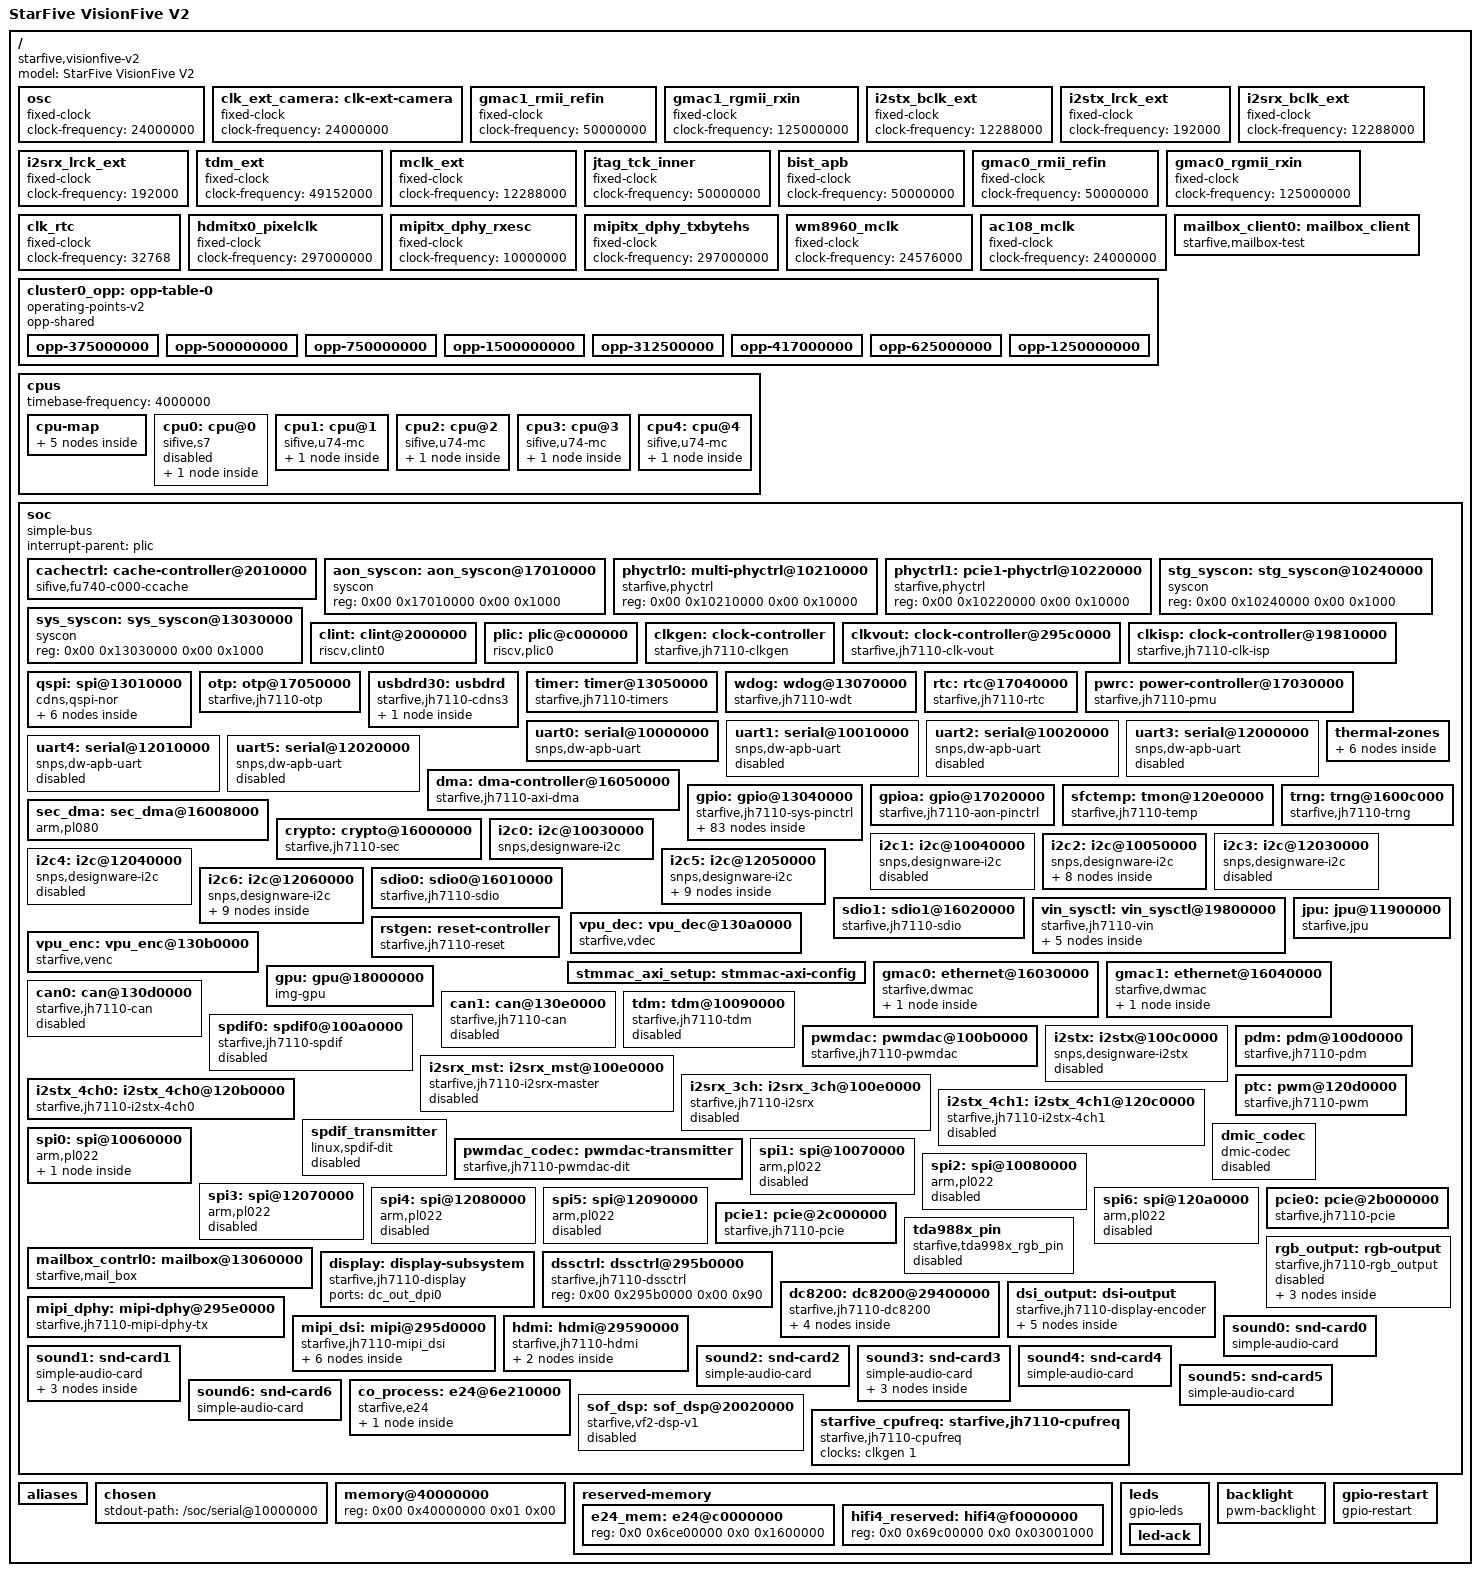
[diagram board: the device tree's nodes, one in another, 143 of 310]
/dts-v1/;

/ {
  compatible     = "starfive,visionfive-v2", "starfive,jh7110";
  #address-cells = <0x02>;
  #size-cells    = <0x02>;
  model          = "StarFive VisionFive V2";

  osc: osc {
    compatible      = "fixed-clock";
    #clock-cells    = <0x00>;
    clock-frequency = <24000000>;
  };

  clk_ext_camera: clk-ext-camera {
    compatible      = "fixed-clock";
    #clock-cells    = <0x00>;
    clock-frequency = <24000000>;
  };

  gmac1_rmii_refin: gmac1_rmii_refin {
    compatible      = "fixed-clock";
    #clock-cells    = <0x00>;
    clock-frequency = <50000000>;
  };

  gmac1_rgmii_rxin: gmac1_rgmii_rxin {
    compatible      = "fixed-clock";
    #clock-cells    = <0x00>;
    clock-frequency = <125000000>;
  };

  i2stx_bclk_ext: i2stx_bclk_ext {
    compatible      = "fixed-clock";
    #clock-cells    = <0x00>;
    clock-frequency = <12288000>;
  };

  i2stx_lrck_ext: i2stx_lrck_ext {
    compatible      = "fixed-clock";
    #clock-cells    = <0x00>;
    clock-frequency = <192000>;
  };

  i2srx_bclk_ext: i2srx_bclk_ext {
    compatible      = "fixed-clock";
    #clock-cells    = <0x00>;
    clock-frequency = <12288000>;
  };

  i2srx_lrck_ext: i2srx_lrck_ext {
    compatible      = "fixed-clock";
    #clock-cells    = <0x00>;
    clock-frequency = <192000>;
  };

  tdm_ext: tdm_ext {
    compatible      = "fixed-clock";
    #clock-cells    = <0x00>;
    clock-frequency = <49152000>;
  };

  mclk_ext: mclk_ext {
    compatible      = "fixed-clock";
    #clock-cells    = <0x00>;
    clock-frequency = <12288000>;
  };

  jtag_tck_inner: jtag_tck_inner {
    compatible      = "fixed-clock";
    #clock-cells    = <0x00>;
    clock-frequency = <50000000>;
  };

  bist_apb: bist_apb {
    compatible      = "fixed-clock";
    #clock-cells    = <0x00>;
    clock-frequency = <50000000>;
  };

  gmac0_rmii_refin: gmac0_rmii_refin {
    compatible      = "fixed-clock";
    #clock-cells    = <0x00>;
    clock-frequency = <50000000>;
  };

  gmac0_rgmii_rxin: gmac0_rgmii_rxin {
    compatible      = "fixed-clock";
    #clock-cells    = <0x00>;
    clock-frequency = <125000000>;
  };

  clk_rtc: clk_rtc {
    compatible      = "fixed-clock";
    #clock-cells    = <0x00>;
    clock-frequency = <32768>;
  };

  hdmitx0_pixelclk: hdmitx0_pixelclk {
    compatible      = "fixed-clock";
    #clock-cells    = <0x00>;
    clock-frequency = <297000000>;
  };

 mipitx_dphy_rxesc: mipitx_dphy_rxesc {
    compatible      = "fixed-clock";
    #clock-cells    = <0x00>;
    clock-frequency = <10000000>;
  };

  mipitx_dphy_txbytehs: mipitx_dphy_txbytehs {
    compatible      = "fixed-clock";
    #clock-cells    = <0x00>;
    clock-frequency = <297000000>;
  };

  wm8960_mclk: wm8960_mclk {
    compatible      = "fixed-clock";
    #clock-cells    = <0x00>;
    clock-frequency = <24576000>;
  };

  ac108_mclk: ac108_mclk {
    compatible      = "fixed-clock";
    #clock-cells    = <0x00>;
    clock-frequency = <24000000>;
  };

  cluster0_opp: opp-table-0 {
    compatible = "operating-points-v2";
    opp-shared;

    opp-375000000 {
      opp-hz        = /bits/ 64 <375000000>;
      opp-microvolt = <800000>;
    };

    opp-500000000 {
      opp-hz        = /bits/ 64 <500000000>;
      opp-microvolt = <800000>;
    };

    opp-750000000 {
      opp-hz        = /bits/ 64 <750000000>;
      opp-microvolt = <800000>;
      opp-suspend;
    };

    opp-1500000000 {
      opp-hz        = /bits/ 64 <1500000000>;
      opp-microvolt = <1040000>;
    };

    opp-312500000 {
      opp-hz        = /bits/ 64 <312500000>;
      opp-microvolt = <800000>;
    };

    opp-417000000 {
      opp-hz        = /bits/ 64 <417000000>;
      opp-microvolt = <800000>;
    };

    opp-625000000 {
      opp-hz        = /bits/ 64 <625000000>;
      opp-microvolt = <800000>;
      opp-suspend;
    };

    opp-1250000000 {
      opp-hz        = /bits/ 64 <1250000000>;
      opp-microvolt = <1000000>;
    };
  };

  cpus {
    #address-cells     = <0x01>;
    #size-cells        = <0x00>;
    timebase-frequency = <4000000>;

    cpu-map {
      cluster0 {
        core0 {
          cpu = <&cpu1>;
        };

        core1 {
          cpu = <&cpu2>;
        };

        core2 {
          cpu = <&cpu3>;
        };

        core3 {
          cpu = <&cpu4>;
        };
      };
    };

    cpu0: cpu@0 {
      compatible         = "sifive,s7", "riscv";
      reg                = <0x00>;
      d-cache-block-size = <0x40>;
      d-cache-sets       = <0x40>;
      d-cache-size       = <0x2000>;
      d-tlb-sets         = <0x01>;
      d-tlb-size         = <0x28>;
      device_type        = "cpu";
      i-cache-block-size = <0x40>;
      i-cache-sets       = <0x40>;
      i-cache-size       = <0x4000>;
      i-tlb-sets         = <0x01>;
      i-tlb-size         = <0x28>;
      mmu-type           = "riscv,sv39";
      next-level-cache   = <&cachectrl>;
      riscv,isa          = "rv64imac_zba_zbb";
      tlb-split;
      #cooling-cells     = <0x02>;
      status             = "disabled";

      cpu0intctrl: interrupt-controller {
        #interrupt-cells = <0x01>;
        compatible       = "riscv,cpu-intc";
        interrupt-controller;
      };
    };

    cpu1: cpu@1 {
      compatible          = "sifive,u74-mc", "riscv";
      reg                 = <0x01>;
      d-cache-block-size  = <0x40>;
      d-cache-sets        = <0x40>;
      d-cache-size        = <0x8000>;
      d-tlb-sets          = <0x01>;
      d-tlb-size          = <0x28>;
      device_type         = "cpu";
      i-cache-block-size  = <0x40>;
      i-cache-sets        = <0x40>;
      i-cache-size        = <0x8000>;
      i-tlb-sets          = <0x01>;
      i-tlb-size          = <0x28>;
      mmu-type            = "riscv,sv39";
      next-level-cache    = <&cachectrl>;
      riscv,isa           = "rv64imafdc_zba_zbb";
      tlb-split;
      #cooling-cells      = <0x02>;
      status              = "okay";
      operating-points-v2 = <&cluster0_opp>;
      cpu-supply          = <&cpu_vdd>;
      clocks              = <&clkgen 1>;
      clock-names         = "cpu";

      cpu1intctrl: interrupt-controller {
        #interrupt-cells = <0x01>;
        compatible       = "riscv,cpu-intc";
        interrupt-controller;
      };
    };

    cpu2: cpu@2 {
      compatible          = "sifive,u74-mc", "riscv";
      reg                 = <0x02>;
      d-cache-block-size  = <0x40>;
      d-cache-sets        = <0x40>;
      d-cache-size        = <0x8000>;
      d-tlb-sets          = <0x01>;
      d-tlb-size          = <0x28>;
      device_type         = "cpu";
      i-cache-block-size  = <0x40>;
      i-cache-sets        = <0x40>;
      i-cache-size        = <0x8000>;
      i-tlb-sets          = <0x01>;
      i-tlb-size          = <0x28>;
      mmu-type            = "riscv,sv39";
      next-level-cache    = <&cachectrl>;
      riscv,isa           = "rv64imafdc_zba_zbb";
      tlb-split;
      #cooling-cells      = <0x02>;
      status              = "okay";
      operating-points-v2 = <&cluster0_opp>;

      cpu2intctrl: interrupt-controller {
        #interrupt-cells = <0x01>;
        compatible       = "riscv,cpu-intc";
        interrupt-controller;
      };
    };

    cpu3: cpu@3 {
      compatible          = "sifive,u74-mc", "riscv";
      reg                 = <0x03>;
      d-cache-block-size  = <0x40>;
      d-cache-sets        = <0x40>;
      d-cache-size        = <0x8000>;
      d-tlb-sets          = <0x01>;
      d-tlb-size          = <0x28>;
      device_type         = "cpu";
      i-cache-block-size  = <0x40>;
      i-cache-sets        = <0x40>;
      i-cache-size        = <0x8000>;
      i-tlb-sets          = <0x01>;
      i-tlb-size          = <0x28>;
      mmu-type            = "riscv,sv39";
      next-level-cache    = <&cachectrl>;
      riscv,isa           = "rv64imafdc_zba_zbb";
      tlb-split;
      #cooling-cells      = <0x02>;
      status              = "okay";
      operating-points-v2 = <&cluster0_opp>;

      cpu3intctrl: interrupt-controller {
        #interrupt-cells = <0x01>;
        compatible       = "riscv,cpu-intc";
        interrupt-controller;
      };
    };

    cpu4: cpu@4 {
      compatible          = "sifive,u74-mc", "riscv";
      reg                 = <0x04>;
      d-cache-block-size  = <0x40>;
      d-cache-sets        = <0x40>;
      d-cache-size        = <0x8000>;
      d-tlb-sets          = <0x01>;
      d-tlb-size          = <0x28>;
      device_type         = "cpu";
      i-cache-block-size  = <0x40>;
      i-cache-sets        = <0x40>;
      i-cache-size        = <0x8000>;
      i-tlb-sets          = <0x01>;
      i-tlb-size          = <0x28>;
      mmu-type            = "riscv,sv39";
      next-level-cache    = <&cachectrl>;
      riscv,isa           = "rv64imafdc_zba_zbb";
      tlb-split;
      #cooling-cells      = <0x02>;
      status              = "okay";
      operating-points-v2 = <&cluster0_opp>;

      cpu4intctrl: interrupt-controller {
        #interrupt-cells = <0x01>;
        compatible       = "riscv,cpu-intc";
        interrupt-controller;
      };
    };
  };

  mailbox_client0: mailbox_client {
    compatible = "starfive,mailbox-test";
    mbox-names = "rx", "tx";
    mboxes     = <&mailbox_contrl0 0 1>, <&mailbox_contrl0 1 0>;
    status     = "okay";
  };

  soc: soc {
    compatible       = "simple-bus";
    interrupt-parent = <&plic>;
    #address-cells   = <0x02>;
    #size-cells      = <0x02>;
    #clock-cells     = <0x01>;
    ranges;

    cachectrl: cache-controller@2010000 {
      compatible       = "sifive,fu740-c000-ccache", "cache";
      reg              = <0x00 0x2010000 0x00 0x4000 0x00 0x8000000 0x00 0x2000000>;
      reg-names        = "control", "sideband";
      interrupts       = <0x01 0x03 0x04 0x02>;
      cache-block-size = <0x40>;
      cache-level      = <0x02>;
      cache-sets       = <0x800>;
      cache-size       = <0x200000>;
      cache-unified;
      uncached-offset  = <0x04 0x00>;
    };

    aon_syscon: aon_syscon@17010000 {
      compatible = "syscon";
      reg        = <0x00 0x17010000 0x00 0x1000>;
    };

    phyctrl0: multi-phyctrl@10210000 {
      compatible = "starfive,phyctrl";
      reg        = <0x00 0x10210000 0x00 0x10000>;
    };

    phyctrl1: pcie1-phyctrl@10220000 {
      compatible = "starfive,phyctrl";
      reg        = <0x00 0x10220000 0x00 0x10000>;
    };

    stg_syscon: stg_syscon@10240000 {
      compatible = "syscon";
      reg        = <0x00 0x10240000 0x00 0x1000>;
    };

    sys_syscon: sys_syscon@13030000 {
      compatible = "syscon";
      reg        = <0x00 0x13030000 0x00 0x1000>;
    };

    clint: clint@2000000 {
      compatible          = "riscv,clint0";
      reg                 = <0x00 0x2000000 0x00 0x10000>;
      reg-names           = "control";
      interrupts-extended = <
        &cpu0intctrl 3 &cpu0intctrl 7
        &cpu1intctrl 3 &cpu1intctrl 7
        &cpu2intctrl 3 &cpu2intctrl 7
        &cpu3intctrl 3 &cpu3intctrl 7
        &cpu4intctrl 3 &cpu4intctrl 7
      >;
      #interrupt-cells    = <0x01>;
    };

    plic: plic@c000000 {
      compatible          = "riscv,plic0";
      reg                 = <0x00 0xc000000 0x00 0x4000000>;
      reg-names           = "control";
      interrupts-extended = <
        &cpu0intctrl 11
        &cpu1intctrl 11 &cpu1intctrl 9
        &cpu2intctrl 11 &cpu2intctrl 9
        &cpu3intctrl 11 &cpu3intctrl 9
        &cpu4intctrl 11 &cpu4intctrl 9
      >;
      interrupt-controller;
      #interrupt-cells    = <0x01>;
      riscv,max-priority  = <0x07>;
      riscv,ndev          = <0x88>;
    };

    clkgen: clock-controller {
      compatible          = "starfive,jh7110-clkgen";
      reg                 = <0x00 0x13020000 0x00 0x10000>, <0x00 0x10230000 0x00 0x10000>, <0x00 0x17000000 0x00 0x10000>;
      reg-names           = "sys", "stg", "aon";
      clocks              = <&osc>, <&gmac1_rmii_refin>, <&gmac1_rgmii_rxin>, <&i2stx_bclk_ext>, <&i2stx_lrck_ext>, <&i2srx_bclk_ext>, <&i2srx_lrck_ext>, <&tdm_ext>, <&mclk_ext>, <&jtag_tck_inner>, <&bist_apb>, <&clk_rtc>, <&gmac0_rmii_refin>, <&gmac0_rgmii_rxin>;
      clock-names         = "osc", "gmac1_rmii_refin", "gmac1_rgmii_rxin", "i2stx_bclk_ext", "i2stx_lrck_ext", "i2srx_bclk_ext", "i2srx_lrck_ext", "tdm_ext", "mclk_ext", "jtag_tck_inner", "bist_apb", "clk_rtc", "gmac0_rmii_refin", "gmac0_rgmii_rxin";
      #clock-cells        = <0x01>;
      starfive,sys-syscon = <&sys_syscon 0x18 0x1c 0x20 0x24 0x28 0x2c 0x30 0x34>;
      status              = "okay";
    };

    clkvout: clock-controller@295c0000 {
      compatible    = "starfive,jh7110-clk-vout";
      reg           = <0x00 0x295c0000 0x00 0x10000>;
      reg-names     = "vout";
      clocks        = <&hdmitx0_pixelclk>, <&mipitx_dphy_rxesc>, <&mipitx_dphy_txbytehs>, <&clkgen 58>, <&clkgen 61>;
      clock-names   = "hdmitx0_pixelclk", "mipitx_dphy_rxesc", "mipitx_dphy_txbytehs", "vout_src", "vout_top_ahb";
      resets        = <&rstgen 43>;
      reset-names   = "vout_src";
      #clock-cells  = <0x01>;
      power-domains = <&pwrc 4>;
      status        = "okay";
    };

    clkisp: clock-controller@19810000 {
      compatible    = "starfive,jh7110-clk-isp";
      reg           = <0x00 0x19810000 0x00 0x10000>;
      reg-names     = "isp";
      #clock-cells  = <0x01>;
      clocks        = <&clkgen 266>, <&clkgen 51>, <&clkgen 52>, <&clkgen 53>;
      clock-names   = "u0_dom_isp_top_clk_dom_isp_top_clk_dvp", "u0_dom_isp_top_clk_dom_isp_top_clk_ispcore_2x", "u0_dom_isp_top_clk_dom_isp_top_clk_isp_axi", "u0_sft7110_noc_bus_clk_isp_axi";
      resets        = <&rstgen 41>, <&rstgen 42>, <&rstgen 28>;
      reset-names   = "rst_isp_top_n", "rst_isp_top_axi", "rst_isp_noc_bus_n";
      power-domains = <&pwrc 5>;
      status        = "okay";
    };

    qspi: spi@13010000 {
      compatible           = "cdns,qspi-nor";
      #address-cells       = <0x01>;
      #size-cells          = <0x00>;
      reg                  = <0x00 0x13010000 0x00 0x10000>, <0x00 0x21000000 0x00 0x400000>;
      interrupts           = <0x19>;
      clocks               = <&clkgen 90>, <&clkgen 88>, <&clkgen 10>, <&clkgen 87>, <&clkgen 89>;
      clock-names          = "clk_ref", "clk_apb", "ahb1", "clk_ahb", "clk_src";
      resets               = <&rstgen 62>, <&rstgen 61>, <&rstgen 63>;
      cdns,fifo-depth      = <0x100>;
      cdns,fifo-width      = <0x04>;
      cdns,trigger-address = <0x00>;
      spi-max-frequency    = <0xee6b280>;

      nor_flash: nor-flash@0 {
        compatible        = "jedec,spi-nor";
        reg               = <0x00>;
        cdns,read-delay   = <0x05>;
        spi-max-frequency = <100000000>;
        cdns,tshsl-ns     = <0x01>;
        cdns,tsd2d-ns     = <0x01>;
        cdns,tchsh-ns     = <0x01>;
        cdns,tslch-ns     = <0x01>;
        status            = "okay";

        partitions {
          compatible     = "fixed-partitions";
          #address-cells = <0x01>;
          #size-cells    = <0x01>;

          spl@0 {
            reg = <0x00 0x40000>;
          };

          uboot-env@100000 {
            reg = <0xf0000 0x10000>;
          };

          uboot@100000 {
            reg = <0x100000 0x300000>;
          };

          data@f00000 {
            reg = <0xf00000 0x100000>;
          };
        };
      };
    };

    otp: otp@17050000 {
      compatible      = "starfive,jh7110-otp";
      reg             = <0x00 0x17050000 0x00 0x10000>;
      clock-frequency = <4000000>;
      clocks          = <&clkgen 228>;
      clock-names     = "apb";
    };

    usbdrd30: usbdrd {
      compatible          = "starfive,jh7110-cdns3";
      reg                 = <0x00 0x10210000 0x00 0x1000>, <0x00 0x10200000 0x00 0x1000>;
      clocks              = <&clkgen 95>, <&clkgen 196>, <&clkgen 194>, <&clkgen 195>, <&clkgen 191>, <&clkgen 193>, <&clkgen 192>;
      clock-names         = "125m", "app", "lpm", "stb", "apb", "axi", "utmi";
      resets              = <&rstgen 138>, <&rstgen 136>, <&rstgen 135>, <&rstgen 137>;
      reset-names         = "pwrup", "apb", "axi", "utmi";
      starfive,stg-syscon = <&stg_syscon 0x04 0xc4 0x148 0x1f4>;
      starfive,sys-syscon = <&sys_syscon 0x18>;
      status              = "okay";
      #address-cells      = <0x02>;
      #size-cells         = <0x02>;
      #interrupt-cells    = <0x01>;
      ranges;
      starfive,usb2-only;
      dr_mode             = "peripheral";

      usbdrd_cdns3: usb@10100000 {
        compatible      = "cdns,usb3";
        dma-coherent;
        reg             = <0x00 0x10100000 0x00 0x10000>, <0x00 0x10110000 0x00 0x10000>, <0x00 0x10120000 0x00 0x10000>;
        reg-names       = "otg", "xhci", "dev";
        interrupts      = <0x64 0x6c 0x6e>;
        interrupt-names = "host", "peripheral", "otg";
        phy-names       = "cdns3,usb3-phy", "cnds3,usb2-phy";
        maximum-speed   = "super-speed";
      };
    };

    timer: timer@13050000 {
      compatible      = "starfive,jh7110-timers";
      reg             = <0x00 0x13050000 0x00 0x10000>;
      interrupts      = <0x45 0x46 0x47 0x48>;
      interrupt-names = "timer0", "timer1", "timer2", "timer3";
      clocks          = <&clkgen 125>, <&clkgen 126>, <&clkgen 127>, <&clkgen 128>, <&clkgen 124>;
      clock-names     = "timer0", "timer1", "timer2", "timer3", "apb_clk";
      resets          = <&rstgen 118>, <&rstgen 119>, <&rstgen 120>, <&rstgen 121>, <&rstgen 117>;
      reset-names     = "timer0", "timer1", "timer2", "timer3", "apb_rst";
      clock-frequency = <0x16e3600>;
      status          = "okay";
    };

    wdog: wdog@13070000 {
      compatible      = "starfive,jh7110-wdt";
      reg             = <0x00 0x13070000 0x00 0x10000>;
      interrupts      = <0x44>;
      interrupt-names = "wdog";
      clocks          = <&clkgen 123>, <&clkgen 122>;
      clock-names     = "core_clk", "apb_clk";
      resets          = <&rstgen 109>, <&rstgen 110>;
      reset-names     = "rst_apb", "rst_core";
      timeout-sec     = <0x0f>;
      status          = "okay";
    };

    rtc: rtc@17040000 {
      compatible         = "starfive,jh7110-rtc";
      reg                = <0x00 0x17040000 0x00 0x10000>;
      interrupts         = <0x0a 0x0b 0x0c>;
      interrupt-names    = "rtc_ms_pulse", "rtc_sec_pulse", "rtc";
      clocks             = <&clkgen 229>, <&clkgen 232>;
      clock-names        = "pclk", "cal_clk";
      resets             = <&rstgen 167>, <&rstgen 165>, <&rstgen 166>;
      reset-names        = "rst_osc", "rst_apb", "rst_cal";
      rtc,cal-clock-freq = <1000000>;
      status             = "okay";
    };

    pwrc: power-controller@17030000 {
      compatible          = "starfive,jh7110-pmu";
      reg                 = <0x00 0x17030000 0x00 0x10000>;
      interrupts          = <0x6f>;
      #power-domain-cells = <0x01>;
      status              = "okay";
    };

    uart0: serial@10000000 {
      compatible    = "snps,dw-apb-uart";
      reg           = <0x00 0x10000000 0x00 0x10000>;
      reg-io-width  = <0x04>;
      reg-shift     = <0x02>;
      clocks        = <&clkgen 146>, <&clkgen 145>;
      clock-names   = "baudclk", "apb_pclk";
      resets        = <&rstgen 83>, <&rstgen 84>;
      interrupts    = <0x20>;
      status        = "okay";
      pinctrl-names = "default";
      pinctrl-0     = <&uart0_pins>;
    };

    uart1: serial@10010000 {
      compatible   = "snps,dw-apb-uart";
      reg          = <0x00 0x10010000 0x00 0x10000>;
      reg-io-width = <0x04>;
      reg-shift    = <0x02>;
      clocks       = <&clkgen 148>, <&clkgen 147>;
      clock-names  = "baudclk", "apb_pclk";
      resets       = <&rstgen 85>, <&rstgen 86>;
      interrupts   = <0x21>;
      status       = "disabled";
    };

    uart2: serial@10020000 {
      compatible   = "snps,dw-apb-uart";
      reg          = <0x00 0x10020000 0x00 0x10000>;
      reg-io-width = <0x04>;
      reg-shift    = <0x02>;
      clocks       = <&clkgen 150>, <&clkgen 149>;
      clock-names  = "baudclk", "apb_pclk";
      resets       = <&rstgen 87>, <&rstgen 88>;
      interrupts   = <0x22>;
      status       = "disabled";
    };

    uart3: serial@12000000 {
      compatible   = "snps,dw-apb-uart";
      reg          = <0x00 0x12000000 0x00 0x10000>;
      reg-io-width = <0x04>;
      reg-shift    = <0x02>;
      clocks       = <&clkgen 152>, <&clkgen 151>;
      clock-names  = "baudclk", "apb_pclk";
      resets       = <&rstgen 89>, <&rstgen 90>;
      interrupts   = <0x2d>;
      status       = "disabled";
    };

    uart4: serial@12010000 {
      compatible   = "snps,dw-apb-uart";
      reg          = <0x00 0x12010000 0x00 0x10000>;
      reg-io-width = <0x04>;
      reg-shift    = <0x02>;
      clocks       = <&clkgen 154>, <&clkgen 153>;
      clock-names  = "baudclk", "apb_pclk";
      resets       = <&rstgen 91>, <&rstgen 92>;
      interrupts   = <0x2e>;
      status       = "disabled";
    };

    uart5: serial@12020000 {
      compatible   = "snps,dw-apb-uart";
      reg          = <0x00 0x12020000 0x00 0x10000>;
      reg-io-width = <0x04>;
      reg-shift    = <0x02>;
      clocks       = <&clkgen 156>, <&clkgen 155>;
      clock-names  = "baudclk", "apb_pclk";
      resets       = <&rstgen 93>, <&rstgen 94>;
      interrupts   = <0x2f>;
      status       = "disabled";
    };

    dma: dma-controller@16050000 {
      compatible             = "starfive,jh7110-axi-dma";
      dma-coherent;
      reg                    = <0x00 0x16050000 0x00 0x10000>;
      clocks                 = <&clkgen 217>, <&clkgen 218>, <&clkgen 96>;
      clock-names            = "core-clk", "cfgr-clk", "noc-clk";
      resets                 = <&rstgen 133>, <&rstgen 134>, <&rstgen 30>;
      interrupts             = <0x49>;
      #dma-cells             = <0x01>;
      dma-channels           = <0x04>;
      snps,dma-masters       = <0x01>;
      snps,data-width        = <0x03>;
      snps,block-size        = <0x10000 0x10000 0x10000 0x10000>;
      snps,priority          = <0x00 0x01 0x02 0x03>;
      snps,axi-max-burst-len = <0x0f>;
      status                 = "okay";
    };

    gpio: gpio@13040000 {
      compatible  = "starfive,jh7110-sys-pinctrl";
      reg         = <0x00 0x13040000 0x00 0x10000>;
      reg-names   = "control";
      clocks      = <&clkgen 112>;
      resets      = <&rstgen 2>;
      interrupts  = <0x56>;
      interrupt-controller;
      #gpio-cells = <0x02>;
      ngpios      = <0x40>;
      status      = "okay";

      i2c0_pins: i2c0-pins {
        i2c0-pins-scl {
          starfive,pins          = <0x39>;
          starfive,pinmux        = <0x2ac 0x0c 0x7000 0x00>;
          starfive,pin-ioconfig  = <0x09>;
          starfive,pin-gpio-dout = <0x00>;
          starfive,pin-gpio-doen = <0x05>;
          starfive,pin-gpio-din  = <0x09>;
        };

        i2c0-pins-sda {
          starfive,pins          = <0x3a>;
          starfive,pinmux        = <0x2ac 0x0f 0x38000 0x00>;
          starfive,pin-ioconfig  = <0x09>;
          starfive,pin-gpio-dout = <0x00>;
          starfive,pin-gpio-doen = <0x06>;
          starfive,pin-gpio-din  = <0x0a>;
        };
      };

      i2c5_pins: i2c5-pins {
        i2c5-pins-scl {
          starfive,pins          = <0x13>;
          starfive,pinmux        = <0x29c 0x1d 0xe0000000 0x00>;
          starfive,pin-ioconfig  = <0x09>;
          starfive,pin-gpio-dout = <0x00>;
          starfive,pin-gpio-doen = <0x2a>;
          starfive,pin-gpio-din  = <0x4f>;
        };

        i2c5-pins-sda {
          starfive,pins          = <0x14>;
          starfive,pinmux        = <0x2a0 0x00 0x07 0x00>;
          starfive,pin-ioconfig  = <0x09>;
          starfive,pin-gpio-dout = <0x00>;
          starfive,pin-gpio-doen = <0x2b>;
          starfive,pin-gpio-din  = <0x50>;
        };
      };

      i2c6_pins: i2c6-pins {
        i2c6-pins-scl {
          starfive,pins          = <0x10>;
          starfive,pinmux        = <0x29c 0x14 0x700000 0x00>;
          starfive,pin-ioconfig  = <0x09>;
          starfive,pin-gpio-dout = <0x00>;
          starfive,pin-gpio-doen = <0x2e>;
          starfive,pin-gpio-din  = <0x56>;
        };

        i2c6-pins-sda {
          starfive,pins          = <0x11>;
          starfive,pinmux        = <0x29c 0x17 0x3800000 0x00>;
          starfive,pin-ioconfig  = <0x09>;
          starfive,pin-gpio-dout = <0x00>;
          starfive,pin-gpio-doen = <0x2f>;
          starfive,pin-gpio-din  = <0x57>;
        };
      };

      pwmdac0_pins: pwmdac0-pins {
        pwmdac0-pins-left {
          starfive,pins          = <0x21>;
          starfive,pinmux        = <0x2a4 0x09 0xe00 0x00>;
          starfive,pin-ioconfig  = <0x09>;
          starfive,pin-gpio-dout = <0x1c>;
          starfive,pin-gpio-doen = <0x00>;
        };

        pwmdac0-pins-right {
          starfive,pins          = <0x22>;
          starfive,pinmux        = <0x2a4 0x0c 0x7000 0x00>;
          starfive,pin-ioconfig  = <0x09>;
          starfive,pin-gpio-dout = <0x1d>;
          starfive,pin-gpio-doen = <0x00>;
        };
      };

      pwm_pins: pwm-pins {
        pwm_ch0-pins {
          starfive,pins          = <0x2e>;
          starfive,pinmux        = <0x2a8 0x0f 0x38000 0x00>;
          starfive,pin-ioconfig  = <0x01>;
          starfive,pin-gpio-dout = <0x18>;
          starfive,pin-gpio-doen = <0x09>;
        };

        pwm_ch1-pins {
          starfive,pins          = <0x3b>;
          starfive,pinmux        = <0x2ac 0x12 0x1c0000 0x00>;
          starfive,pin-ioconfig  = <0x01>;
          starfive,pin-gpio-dout = <0x19>;
          starfive,pin-gpio-doen = <0x0a>;
        };

        pwm_ch2-pins {
          starfive,pins          = <0x18>;
          starfive,pinmux        = <0x2a0 0x0c 0x7000 0x00>;
          starfive,pin-ioconfig  = <0x01>;
          starfive,pin-gpio-dout = <0x1a>;
          starfive,pin-gpio-doen = <0x0b>;
        };
      };

      ssp0_pins: ssp0-pins {
        ssp0-pins_tx {
          starfive,pins          = <0x34>;
          starfive,pinmux        = <0x2ac 0x00 0x03 0x00>;
          starfive,pin-ioconfig  = <0x01>;
          starfive,pin-gpio-dout = <0x20>;
          starfive,pin-gpio-doen = <0x00>;
        };

        ssp0-pins_rx {
          starfive,pins          = <0x35>;
          starfive,pinmux        = <0x2ac 0x02 0x0c 0x00>;
          starfive,pin-ioconfig  = <0x01>;
          starfive,pin-gpio-doen = <0x01>;
          starfive,pin-gpio-din  = <0x1c>;
        };

        ssp0-pins_clk {
          starfive,pins          = <0x30>;
          starfive,pinmux        = <0x2a8 0x15 0xe00000 0x00>;
          starfive,pin-ioconfig  = <0x01>;
          starfive,pin-gpio-dout = <0x1e>;
          starfive,pin-gpio-doen = <0x00>;
        };

        ssp0-pins_cs {
          starfive,pins          = <0x31>;
          starfive,pinmux        = <0x2a8 0x18 0x7000000 0x00>;
          starfive,pin-ioconfig  = <0x01>;
          starfive,pin-gpio-dout = <0x1f>;
          starfive,pin-gpio-doen = <0x00>;
        };
      };

      pcie0_perst_default: pcie0_perst_default {
        perst-pins {
          starfive,pins          = <0x1a>;
          starfive,pinmux        = <0x2a0 0x12 0x1c0000 0x00>;
          starfive,pin-ioconfig  = <0x01>;
          starfive,pin-gpio-dout = <0x01>;
          starfive,pin-gpio-doen = <0x00>;
        };
      };

      pcie0_perst_active: pcie0_perst_active {
        perst-pins {
          starfive,pins          = <0x1a>;
          starfive,pinmux        = <0x2a0 0x12 0x1c0000 0x00>;
          starfive,pin-ioconfig  = <0x01>;
          starfive,pin-gpio-dout = <0x00>;
          starfive,pin-gpio-doen = <0x00>;
        };
      };

      pcie0_wake_default: pcie0_wake_default {
        wake-pins {
          starfive,pins          = <0x20>;
          starfive,pinmux        = <0x2a4 0x06 0x1c0 0x00>;
          starfive,pin-ioconfig  = <0x01>;
          starfive,pin-gpio-doen = <0x01>;
        };
      };

      pcie0_clkreq_default: pcie0_clkreq_default {
        clkreq-pins {
          starfive,pins          = <0x1b>;
          starfive,pinmux        = <0x2a0 0x15 0xe00000 0x00>;
          starfive,pin-ioconfig  = <0x01>;
          starfive,pin-gpio-doen = <0x01>;
        };
      };

      pcie1_perst_default: pcie1_perst_default {
        perst-pins {
          starfive,pins          = <0x1c>;
          starfive,pinmux        = <0x2a0 0x18 0x7000000 0x00>;
          starfive,pin-ioconfig  = <0x01>;
          starfive,pin-gpio-dout = <0x01>;
          starfive,pin-gpio-doen = <0x00>;
        };
      };

      pcie1_perst_active: pcie1_perst_active {
        perst-pins {
          starfive,pins          = <0x1c>;
          starfive,pinmux        = <0x2a0 0x18 0x7000000 0x00>;
          starfive,pin-ioconfig  = <0x01>;
          starfive,pin-gpio-dout = <0x00>;
          starfive,pin-gpio-doen = <0x00>;
        };
      };

      pcie1_wake_default: pcie1_wake_default {
        wake-pins {
          starfive,pins          = <0x15>;
          starfive,pinmux        = <0x2a0 0x03 0x38 0x00>;
          starfive,pin-ioconfig  = <0x01>;
          starfive,pin-gpio-doen = <0x01>;
        };
      };

      pcie1_clkreq_default: pcie1_clkreq_default {
        clkreq-pins {
          starfive,pins          = <0x1d>;
          starfive,pinmux        = <0x2a0 0x1b 0x38000000 0x00>;
          starfive,pin-ioconfig  = <0x01>;
          starfive,pin-gpio-doen = <0x01>;
        };
      };

      usb_pins: usb-pins {
        drive-vbus-pin {
          starfive,pins          = <0x19>;
          starfive,pinmux        = <0x2a0 0x0f 0x38000 0x00>;
          starfive,pin-ioconfig  = <0x01>;
          starfive,pin-gpio-dout = <0x07>;
          starfive,pin-gpio-doen = <0x00>;
        };
      };

      i2srx_pins: i2srx-pins {
        i2srx-pins0 {
          starfive,pins          = <0x3d>;
          starfive,pinmux        = <0x2ac 0x18 0x7000000 0x00>;
          starfive,pin-ioconfig  = <0x01>;
          starfive,pin-gpio-doen = <0x01>;
          starfive,pin-gpio-din  = <0x17>;
        };
      };

      i2s_clk_pins: i2s-clk0 {
        i2s-clk0_bclk {
          starfive,pins          = <0x26>;
          starfive,pinmux        = <0x2a4 0x17 0x3800000 0x00>;
          starfive,pin-ioconfig  = <0x01>;
          starfive,pin-gpio-din  = <0x21 0x1f>;
          starfive,pin-gpio-doen = <0x01>;
        };

        i2s-clk0_lrclk {
          starfive,pins          = <0x3f>;
          starfive,pinmux        = <0x2ac 0x1e 0xc0000000 0x00>;
          starfive,pin-ioconfig  = <0x01>;
          starfive,pin-gpio-din  = <0x22 0x20>;
          starfive,pin-gpio-doen = <0x01>;
        };
      };

      i2stx_pins: i2stx-pins {
        i2stx-pins0 {
          starfive,pins          = <0x2c>;
          starfive,pinmux        = <0x2a8 0x09 0xe00 0x00>;
          starfive,pin-ioconfig  = <0x01>;
          starfive,pin-gpio-dout = <0x45>;
          starfive,pin-gpio-doen = <0x00>;
        };
      };

      uart0_pins: uart0-pins {
        uart0-pins-tx {
          starfive,pins          = <0x05>;
          starfive,pin-ioconfig  = <0x07>;
          starfive,pin-gpio-dout = <0x14>;
          starfive,pin-gpio-doen = <0x00>;
        };

        uart0-pins-rx {
          starfive,pins          = <0x06>;
          starfive,pinmux        = <0x2b0 0x00 0x03 0x00>;
          starfive,pin-ioconfig  = <0x09>;
          starfive,pin-gpio-doen = <0x01>;
          starfive,pin-gpio-din  = <0x0e>;
        };
      };

      i2c2_pins: i2c2-pins {
        i2c2-pins-scl {
          starfive,pins          = <0x03>;
          starfive,pin-ioconfig  = <0x09>;
          starfive,pin-gpio-dout = <0x00>;
          starfive,pin-gpio-doen = <0x1e>;
          starfive,pin-gpio-din  = <0x3b>;
        };

        i2c2-pins-sda {
          starfive,pins          = <0x02>;
          starfive,pin-ioconfig  = <0x09>;
          starfive,pin-gpio-dout = <0x00>;
          starfive,pin-gpio-doen = <0x1f>;
          starfive,pin-gpio-din  = <0x3c>;
        };
      };

      mmc0_pins: mmc0-pins {
        mmc0-pins-rest {
          starfive,pins          = <0x3e>;
          starfive,pinmux        = <0x2ac 0x1b 0x38000000 0x00>;
          starfive,pin-ioconfig  = <0x09>;
          starfive,pin-gpio-dout = <0x13>;
          starfive,pin-gpio-doen = <0x00>;
        };

        mmc0-pins-cLK {
          starfive,pins         = <0x40>;
          starfive,pin-ioconfig = <0x2d>;
        };

        mmc0-pins-cmd {
          starfive,pins         = <0x41>;
          starfive,pin-ioconfig = <0x0b>;
        };

        mmc0-pins-data0 {
          starfive,pins         = <0x42>;
          starfive,pin-ioconfig = <0x0b>;
        };

        mmc0-pins-data1 {
          starfive,pins         = <0x43>;
          starfive,pin-ioconfig = <0x0b>;
        };

        mmc0-pins-data2 {
          starfive,pins         = <0x44>;
          starfive,pin-ioconfig = <0x0b>;
        };

        mmc0-pins-data3 {
          starfive,pins         = <0x45>;
          starfive,pin-ioconfig = <0x0b>;
        };

        mmc0-pins-data4 {
          starfive,pins         = <0x46>;
          starfive,pin-ioconfig = <0x0b>;
        };

        mmc0-pins-data5 {
          starfive,pins         = <0x47>;
          starfive,pin-ioconfig = <0x0b>;
        };

        mmc0-pins-data6 {
          starfive,pins         = <0x48>;
          starfive,pin-ioconfig = <0x0b>;
        };

        mmc0-pins-data7 {
          starfive,pins         = <0x49>;
          starfive,pin-ioconfig = <0x0b>;
        };
      };

      sdcard1_pins: sdcard1-pins {
        sdcard1-pins0 {
          starfive,pins          = <0x0a>;
          starfive,pinmux        = <0x29c 0x02 0x1c 0x00>;
          starfive,pin-ioconfig  = <0x2d>;
          starfive,pin-gpio-dout = <0x37>;
          starfive,pin-gpio-doen = <0x00>;
        };

        sdcard1-pins1 {
          starfive,pins          = <0x09>;
          starfive,pinmux        = <0x2b0 0x08 0x700 0x00>;
          starfive,pin-ioconfig  = <0x0b>;
          starfive,pin-gpio-dout = <0x39>;
          starfive,pin-gpio-doen = <0x13>;
          starfive,pin-gpio-din  = <0x2c>;
        };

        sdcard1-pins2 {
          starfive,pins          = <0x0b>;
          starfive,pinmux        = <0x29c 0x05 0xe0 0x00>;
          starfive,pin-ioconfig  = <0x0b>;
          starfive,pin-gpio-dout = <0x3a>;
          starfive,pin-gpio-doen = <0x14>;
          starfive,pin-gpio-din  = <0x2d>;
        };

        sdcard1-pins3 {
          starfive,pins          = <0x0c>;
          starfive,pinmux        = <0x29c 0x08 0x700 0x00>;
          starfive,pin-ioconfig  = <0x0b>;
          starfive,pin-gpio-dout = <0x3b>;
          starfive,pin-gpio-doen = <0x15>;
          starfive,pin-gpio-din  = <0x2e>;
        };

        sdcard1-pins4 {
          starfive,pins          = <0x07>;
          starfive,pinmux        = <0x2b0 0x02 0x1c 0x00>;
          starfive,pin-ioconfig  = <0x0b>;
          starfive,pin-gpio-dout = <0x3c>;
          starfive,pin-gpio-doen = <0x16>;
          starfive,pin-gpio-din  = <0x2f>;
        };

        sdcard1-pins5 {
          starfive,pins          = <0x08>;
          starfive,pinmux        = <0x2b0 0x05 0xe0 0x00>;
          starfive,pin-ioconfig  = <0x0b>;
          starfive,pin-gpio-dout = <0x3d>;
          starfive,pin-gpio-doen = <0x17>;
          starfive,pin-gpio-din  = <0x30>;
        };
      };

      inno_hdmi_pins: inno_hdmi-pins {
        inno_hdmi-scl {
          starfive,pins          = <0x00>;
          starfive,pin-ioconfig  = <0x09>;
          starfive,pin-gpio-dout = <0x0b>;
          starfive,pin-gpio-doen = <0x03>;
          starfive,pin-gpio-din  = <0x06>;
        };

        inno_hdmi-sda {
          starfive,pins          = <0x01>;
          starfive,pin-ioconfig  = <0x09>;
          starfive,pin-gpio-dout = <0x0c>;
          starfive,pin-gpio-doen = <0x04>;
          starfive,pin-gpio-din  = <0x07>;
        };

        inno_hdmi-cec-pins {
          starfive,pins          = <0x0e>;
          starfive,pin-ioconfig  = <0x09>;
          starfive,pin-gpio-doen = <0x02>;
          starfive,pin-gpio-dout = <0x0a>;
          starfive,pin-gpio-din  = <0x05>;
        };

        inno_hdmi-hpd-pins {
          starfive,pins          = <0x0f>;
          starfive,pin-ioconfig  = <0x01>;
          starfive,pin-gpio-doen = <0x01>;
          starfive,pin-gpio-din  = <0x08>;
        };
      };

      mclk_ext_pins: mclk_ext_pins {
        mclk_ext_pins {
          starfive,pins          = <0x04>;
          starfive,pin-ioconfig  = <0x01>;
          starfive,pin-gpio-din  = <0x1e>;
          starfive,pin-gpio-doen = <0x01>;
        };
      };

     tdm0_pins: tdm0-pins {
        tdm0-pins-tx {
          starfive,pins          = <0x2c>;
          starfive,pinmux        = <0x2a8 0x09 0xe00 0x00>;
          starfive,pin-ioconfig  = <0x01>;
          starfive,pin-gpio-dout = <0x29>;
          starfive,pin-gpio-doen = <0x00>;
        };

        tdm0-pins-rx {
          starfive,pins          = <0x3d>;
          starfive,pinmux        = <0x2ac 0x18 0x7000000 0x00>;
          starfive,pin-ioconfig  = <0x01>;
          starfive,pin-gpio-doen = <0x01>;
          starfive,pin-gpio-din  = <0x24>;
        };

        tdm0-pins-sync {
          starfive,pins          = <0x3f>;
          starfive,pinmux        = <0x2ac 0x1e 0xc0000000 0x00>;
          starfive,pin-ioconfig  = <0x01>;
          starfive,pin-gpio-doen = <0x01>;
          starfive,pin-gpio-din  = <0x25>;
        };

        tdm0-pins-pcmclk {
          starfive,pins          = <0x26>;
          starfive,pinmux        = <0x2a4 0x17 0x3800000 0x00>;
          starfive,pin-ioconfig  = <0x01>;
          starfive,pin-gpio-doen = <0x01>;
          starfive,pin-gpio-din  = <0x23>;
        };
      };
    };

    gpioa: gpio@17020000 {
      compatible  = "starfive,jh7110-aon-pinctrl";
      reg         = <0x00 0x17020000 0x00 0x10000>;
      reg-names   = "control";
      resets      = <&rstgen 162>;
      interrupts  = <0x55>;
      interrupt-controller;
      #gpio-cells = <0x02>;
      ngpios      = <0x04>;
      status      = "okay";
    };

    sfctemp: tmon@120e0000 {
      compatible            = "starfive,jh7110-temp";
      reg                   = <0x00 0x120e0000 0x00 0x10000>;
      interrupts            = <0x51>;
      clocks                = <&clkgen 130>, <&clkgen 129>;
      clock-names           = "sense", "bus";
      resets                = <&rstgen 124>, <&rstgen 123>;
      reset-names           = "sense", "bus";
      #thermal-sensor-cells = <0x00>;
      status                = "okay";
    };

    thermal-zones {
      cpu-thermal {
        polling-delay-passive = <250>;
        polling-delay         = <15000>;
        thermal-sensors       = <&sfctemp>;

        trips {
          cpu_alert0: cpu_alert0 {
            temperature = <85000>;
            hysteresis  = <2000>;
            type        = "passive";
          };

          cpu_crit: cpu_crit {
            temperature = <100000>;
            hysteresis  = <2000>;
            type        = "critical";
          };
        };

        cooling-maps {
          map0 {
            trip = <&cpu_alert0>;
            cooling-device = <&cpu0 (~0) (~0)>,  <&cpu1 (~0) (~0)>, <&cpu2 (~0) (~0)>, <&cpu3 (~0) (~0)>;
          };
        };
      };
    };

    trng: trng@1600c000 {
      compatible  = "starfive,jh7110-trng";
      reg         = <0x00 0x1600c000 0x00 0x4000>;
      clocks      = <&clkgen 205>, <&clkgen 206>;
      clock-names = "hclk", "ahb";
      resets      = <&rstgen 131>;
      interrupts  = <0x1e>;
      status      = "okay";
    };

    sec_dma: sec_dma@16008000 {
      compatible             = "arm,pl080", "arm,primecell";
      dma-coherent;
      arm,primecell-periphid = <0x41080>;
      reg                    = <0x00 0x16008000 0x00 0x4000>;
      reg-names              = "sec_dma";
      interrupts             = <0x1d>;
      clocks                 = <&clkgen 205>, <&clkgen 206>;
      clock-names            = "sec_hclk", "apb_pclk";
      resets                 = <&rstgen 131>;
      reset-names            = "sec_hre";
      lli-bus-interface-ahb1;
      mem-bus-interface-ahb1;
      memcpy-burst-size      = <0x100>;
      memcpy-bus-width       = <0x20>;
      #dma-cells             = <0x02>;
      status                 = "okay";
    };

    crypto: crypto@16000000 {
      compatible                     = "starfive,jh7110-sec";
      dma-coherent;
      reg                            = <0x00 0x16000000 0x00 0x4000>, <0x00 0x16008000 0x00 0x4000>;
      reg-names                      = "secreg", "secdma";
      interrupts                     = <0x1c 0x1d>;
      interrupt-names                = "secirq", "dmairq";
      clocks                         = <&clkgen 205>, <&clkgen 206>;
      clock-names                    = "sec_hclk", "sec_ahb";
      resets                         = <&rstgen 131>;
      reset-names                    = "sec_hre";
      enable-side-channel-mitigation = "true";
      enable-dma                     = "true";
      dmas                           = <&sec_dma 1 2>, <&sec_dma 0 2>;
      dma-names                      = "sec_m", "sec_p";
      status                         = "okay";
    };

    i2c0: i2c@10030000 {
      compatible              = "snps,designware-i2c";
      reg                     = <0x00 0x10030000 0x00 0x10000>;
      clocks                  = <&clkgen 293>, <&clkgen 138>;
      clock-names             = "ref", "pclk";
      resets                  = <&rstgen 76>;
      interrupts              = <0x23>;
      #address-cells          = <0x01>;
      #size-cells             = <0x00>;
      status                  = "okay";
      clock-frequency         = <100000>;
      i2c-sda-hold-time-ns    = <300>;
      i2c-sda-falling-time-ns = <510>;
      i2c-scl-falling-time-ns = <510>;
      auto_calc_scl_lhcnt;
      pinctrl-names           = "default";
      pinctrl-0               = <&i2c0_pins>;
    };

    i2c1: i2c@10040000 {
      compatible     = "snps,designware-i2c";
      reg            = <0x00 0x10040000 0x00 0x10000>;
      clocks         = <&clkgen 294>, <&clkgen 139>;
      clock-names    = "ref", "pclk";
      resets         = <&rstgen 77>;
      interrupts     = <0x24>;
      #address-cells = <0x01>;
      #size-cells    = <0x00>;
      status         = "disabled";
    };

    i2c2: i2c@10050000 {
      compatible              = "snps,designware-i2c";
      reg                     = <0x00 0x10050000 0x00 0x10000>;
      clocks                  = <&clkgen 295>, <&clkgen 140>;
      clock-names             = "ref", "pclk";
      resets                  = <&rstgen 78>;
      interrupts              = <0x25>;
      #address-cells          = <0x01>;
      #size-cells             = <0x00>;
      status                  = "okay";
      clock-frequency         = <100000>;
      i2c-sda-hold-time-ns    = <300>;
      i2c-sda-falling-time-ns = <510>;
      i2c-scl-falling-time-ns = <510>;
      auto_calc_scl_lhcnt;
      pinctrl-names           = "default";
      pinctrl-0               = <&i2c0_pins>;

      seeed_plane_i2c@45 {
        compatible = "seeed_panel";
        reg        = <0x45>;

        port {
          panel_out0: endpoint {
            remote-endpoint = <&dsi0_output>;
          };
        };
      };

      tinker_ft5406: tinker_ft5406@38 {
        compatible = "tinker_ft5406";
        reg        = <0x38>;
      };

      touchscreen@14 {
        compatible  = "goodix,gt911";
        reg         = <0x14>;
        irq-gpios   = <&gpio 30 0>;
        reset-gpios = <&gpio 31 0>;
      };

      panel_radxa@19 {
        compatible  = "starfive_jadard";
        reg         = <0x19>;
        reset-gpio  = <&gpio 23 0>;
        enable-gpio = <&gpio 22 0>;

        port {
          panel_out1: endpoint {
            remote-endpoint = <&dsi1_output>;
          };
        };
      };
    };

    i2c3: i2c@12030000 {
      compatible     = "snps,designware-i2c";
      reg            = <0x00 0x12030000 0x00 0x10000>;
      clocks         = <&clkgen 296>, <&clkgen 141>;
      clock-names    = "ref", "pclk";
      resets         = <&rstgen 79>;
      interrupts     = <0x30>;
      #address-cells = <0x01>;
      #size-cells    = <0x00>;
      status         = "disabled";
    };

    i2c4: i2c@12040000 {
      compatible     = "snps,designware-i2c";
      reg            = <0x00 0x12040000 0x00 0x10000>;
      clocks         = <&clkgen 297>, <&clkgen 142>;
      clock-names    = "ref", "pclk";
      resets         = <&rstgen 80>;
      interrupts     = <0x31>;
      #address-cells = <0x01>;
      #size-cells    = <0x00>;
      status         = "disabled";
    };

    i2c5: i2c@12050000 {
      compatible              = "snps,designware-i2c";
      reg                     = <0x00 0x12050000 0x00 0x10000>;
      clocks                  = <&clkgen 298>, <&clkgen 143>;
      clock-names             = "ref", "pclk";
      resets                  = <&rstgen 81>;
      interrupts              = <0x32>;
      #address-cells          = <0x01>;
      #size-cells             = <0x00>;
      status                  = "okay";
      clock-frequency         = <100000>;
      i2c-sda-hold-time-ns    = <300>;
      i2c-sda-falling-time-ns = <510>;
      i2c-scl-falling-time-ns = <510>;
      auto_calc_scl_lhcnt;
      pinctrl-names           = "default";
      pinctrl-0               = <&i2c5_pins>;

      eeprom@50 {
        compatible = "atmel,24c04";
        reg        = <0x50>;
        pagesize   = <0x10>;
      };

      pmic: axp15060_reg@36 {
        compatible = "stf,axp15060-regulator";
        reg        = <0x36>;

        regulators {
          mipi_0p9: ALDO1 {
            regulator-boot-on;
            regulator-compatible    = "mipi_0p9";
            regulator-name          = "mipi_0p9";
            regulator-min-microvolt = <900000>;
            regulator-max-microvolt = <900000>;
          };

          hdmi_0p9: ALDO5 {
            regulator-boot-on;
            regulator-compatible    = "hdmi_0p9";
            regulator-name          = "hdmi_0p9";
            regulator-min-microvolt = <900000>;
            regulator-max-microvolt = <900000>;
          };

          hdmi_1p8: ALDO3 {
            regulator-boot-on;
            regulator-compatible    = "hdmi_1p8";
            regulator-name          = "hdmi_1p8";
            regulator-min-microvolt = <1800000>;
            regulator-max-microvolt = <1800000>;
          };

          sdio_vdd: ALDO4 {
            regulator-boot-on;
            regulator-always-on;
            regulator-compatible    = "sdio_vdd";
            regulator-name          = "sdio_vdd";
            regulator-min-microvolt = <1800000>;
            regulator-max-microvolt = <1800000>;
          };

          vcc_3v3: DCDC1 {
            regulator-boot-on;
            regulator-always-on;
            regulator-compatible    = "vcc_3v3";
            regulator-name          = "vcc_3v3";
            regulator-min-microvolt = <3300000>;
            regulator-max-microvolt = <3300000>;
          };

          cpu_vdd: DCDC2 {
            regulator-boot-on;
            regulator-always-on;
            regulator-compatible    = "cpu_vdd";
            regulator-name          = "cpu_vdd";
            regulator-min-microvolt = <500000>;
            regulator-max-microvolt = <1540000>;
          };
        };
      };
    };

    i2c6: i2c@12060000 {
      compatible              = "snps,designware-i2c";
      reg                     = <0x00 0x12060000 0x00 0x10000>;
      clocks                  = <&clkgen 299>, <&clkgen 144>;
      clock-names             = "ref", "pclk";
      resets                  = <&rstgen 82>;
      interrupts              = <0x33>;
      #address-cells          = <0x01>;
      #size-cells             = <0x00>;
      status                  = "okay";
      clock-frequency         = <0x186a0>;
      i2c-sda-hold-time-ns    = <0x12c>;
      i2c-sda-falling-time-ns = <0x1fe>;
      i2c-scl-falling-time-ns = <0x1fe>;
      auto_calc_scl_lhcnt;
      pinctrl-names           = "default";
      pinctrl-0               = <&i2c6_pins>;

      imx219: imx219@10 {
        compatible  = "sony,imx219";
        reg         = <0x10>;
        clocks      = <&clk_ext_camera>;
        clock-names = "xclk";
        reset-gpio  = <&gpio 18 0>;
        rotation    = <0x00>;
        orientation = <0x01>;

        port {

          imx219_to_csi2rx0: endpoint {
            remote-endpoint  = <&csi2rx0_from_imx219>;
            bus-type         = <0x04>;
            clock-lanes      = <0x04>;
            data-lanes       = <0x00 0x01>;
            lane-polarities  = <0x00 0x00 0x00>;
            link-frequencies = /bits/ 64 <456000000>;
          };
        };
      };

      imx708: imx708@1a {
        compatible = "sony,imx708";
        reg        = <0x1a>;
        clocks     = <&clk_ext_camera>;
        reset-gpio = <&gpio 18 0>;

        port {
          imx708_to_csi2rx0: endpoint {
            remote-endpoint  = <&csi2rx0_from_imx708>;
            data-lanes       = <0x01 0x02>;
            clock-noncontinuous;
            link-frequencies = /bits/ 64 <450000000>;
          };
        };
      };

      ov4689: ov4689@36 {
        compatible  = "ovti,ov4689";
        reg         = <0x36>;
        clocks      = <&clk_ext_camera>;
        clock-names = "xclk";
        rotation    = <180>;

        port {
          ov4689_to_csi2rx0: endpoint {
            remote-endpoint = <&csi2rx0_from_ov4689>;
            bus-type        = <0x04>;
            clock-lanes     = <0x00>;
            data-lanes      = <0x01 0x02>;
          };
        };
      };
    };

    sdio0: sdio0@16010000 {
      compatible             = "starfive,jh7110-sdio";
      dma-coherent;
      reg                    = <0x00 0x16010000 0x00 0x10000>;
      clocks                 = <&clkgen 91>, <&clkgen 93>;
      clock-names            = "biu", "ciu";
      resets                 = <&rstgen 64>;
      reset-names            = "reset";
      interrupts             = <0x4a>;
      fifo-depth             = <0x20>;
      fifo-watermark-aligned;
      data-addr              = <0x00>;
      status                 = "okay";
      max-frequency          = <100000000>;
      assigned-clocks        = <&clkgen 93>;
      assigned-clock-rates   = <50000000>;
      card-detect-delay      = <300>;
      bus-width              = <0x08>;
      cap-mmc-highspeed;
      mmc-hs200-1_8v;
      non-removable;
      cap-mmc-hw-reset;
      post-power-on-delay-ms = <200>;
      vmmc-supply            = <&vcc_3v3>;
      vqmmc-supply           = <&sdio_vdd>;
      pinctrl-names          = "default";
      pinctrl-0              = <&mmc0_pins>;
    };

    sdio1: sdio1@16020000 {
      compatible             = "starfive,jh7110-sdio";
      dma-coherent;
      reg                    = <0x00 0x16020000 0x00 0x10000>;
      clocks                 = <&clkgen 92>, <&clkgen 94>;
      clock-names            = "biu", "ciu";
      resets                 = <&rstgen 65>;
      reset-names            = "reset";
      interrupts             = <0x4b>;
      fifo-depth             = <0x20>;
      fifo-watermark-aligned;
      data-addr              = <0x00>;
      status                 = "okay";
      max-frequency          = <100000000>;
      assigned-clocks        = <&clkgen 94>;
      assigned-clock-rates   = <50000000>;
      card-detect-delay      = <300>;
      bus-width              = <0x04>;
      cap-sd-highspeed;
      no-sdio;
      no-mmc;
      broken-cd;
      post-power-on-delay-ms = <200>;
      pinctrl-names          = "default";
      pinctrl-0              = <&sdcard1_pins>;
    };

    vin_sysctl: vin_sysctl@19800000 {
      compatible          = "starfive,jh7110-vin";
      reg                 = <0x00 0x19800000 0x00 0x10000>, <0x00 0x19810000 0x00 0x10000>, <0x00 0x19820000 0x00 0x10000>, <0x00 0x19840000 0x00 0x10000>, <0x00 0x19870000 0x00 0x30000>, <0x00 0x11840000 0x00 0x10000>, <0x00 0x17030000 0x00 0x10000>, <0x00 0x13020000 0x00 0x10000>;
      reg-names           = "csi2rx", "vclk", "vrst", "sctrl", "isp", "trst", "pmu", "syscrg";
      clocks              = <&clkisp 0>, <&clkisp 6>, <&clkisp 7>, <&clkisp 13>, <&clkisp 2>, <&clkisp 12>, <&clkisp 1>, <&clkisp 8>, <&clkisp 9>, <&clkisp 10>, <&clkisp 11>, <&clkisp 3>, <&clkisp 4>, <&clkisp 5>, <&clkgen 51>, <&clkgen 52>;
      clock-names         = "clk_apb_func", "clk_pclk", "clk_sys_clk", "clk_wrapper_clk_c", "clk_dvp_inv", "clk_axiwr", "clk_mipi_rx0_pxl", "clk_pixel_clk_if0", "clk_pixel_clk_if1", "clk_pixel_clk_if2", "clk_pixel_clk_if3", "clk_m31dphy_cfgclk_in", "clk_m31dphy_refclk_in", "clk_m31dphy_txclkesc_lan0", "clk_ispcore_2x", "clk_isp_axi";
      resets              = <&rstgen 192>, <&rstgen 193>, <&rstgen 196>, <&rstgen 201>, <&rstgen 202>, <&rstgen 203>, <&rstgen 197>, <&rstgen 198>, <&rstgen 199>, <&rstgen 200>, <&rstgen 194>, <&rstgen 195>, <&rstgen 41>, <&rstgen 42>;
      reset-names         = "rst_wrapper_p", "rst_wrapper_c", "rst_pclk", "rst_sys_clk", "rst_axird", "rst_axiwr", "rst_pixel_clk_if0", "rst_pixel_clk_if1", "rst_pixel_clk_if2", "rst_pixel_clk_if3", "rst_m31dphy_hw", "rst_m31dphy_b09_always_on", "rst_isp_top_n", "rst_isp_top_axi";
      starfive,aon-syscon = <&aon_syscon 0x00>;
      power-domains       = <&pwrc 5>;
      interrupts          = <0x5c 0x57 0x58 0x59 0x5a>;
      status              = "okay";

      ports {
        #address-cells = <0x01>;
        #size-cells    = <0x00>;

        port@1 {
          reg            = <0x01>;
          #address-cells = <0x01>;
          #size-cells    = <0x00>;

          csi2rx0_from_imx219: endpoint@0 {
            reg             = <0x00>;
            remote-endpoint = <&imx219_to_csi2rx0>;
            bus-type        = <0x04>;
            clock-lanes     = <0x04>;
            data-lanes      = <0x00 0x01>;
            lane-polarities = <0x00 0x00 0x00>;
            status          = "okay";
          };

          csi2rx0_from_imx708: endpoint@1 {
            reg             = <0x01>;
            remote-endpoint = <&imx708_to_csi2rx0>;
            bus-type        = <0x04>;
            clock-lanes     = <0x04>;
            data-lanes      = <0x00 0x01>;
            lane-polarities = <0x00 0x00 0x00>;
            status          = "okay";
          };

          csi2rx0_from_ov4689: endpoint@2 {
            reg             = <0x02>;
            remote-endpoint = <&ov4689_to_csi2rx0>;
            bus-type        = <0x04>;
            clock-lanes     = <0x04>;
            data-lanes      = <0x00 0x01>;
            status          = "okay";
          };
        };
      };
    };

    jpu: jpu@11900000 {
      compatible    = "starfive,jpu";
      dma-coherent;
      reg           = <0x00 0x13090000 0x00 0x300>;
      interrupts    = <0x0e>;
      clocks        = <&clkgen 66>, <&clkgen 67>, <&clkgen 68>, <&clkgen 76>;
      clock-names   = "axi_clk", "core_clk", "apb_clk", "noc_bus";
      resets        = <&rstgen 44>, <&rstgen 45>, <&rstgen 46>;
      reset-names   = "rst_axi", "rst_core", "rst_apb";
      power-domains = <&pwrc 3>;
      status        = "okay";
    };

    vpu_dec: vpu_dec@130a0000 {
      compatible    = "starfive,vdec";
      dma-coherent;
      reg           = <0x00 0x130a0000 0x00 0x10000>;
      interrupts    = <0x0d>;
      clocks        = <&clkgen 70>, <&clkgen 71>, <&clkgen 72>, <&clkgen 73>, <&clkgen 76>;
      clock-names   = "axi_clk", "bpu_clk", "vce_clk", "apb_clk", "noc_bus";
      resets        = <&rstgen 47>, <&rstgen 48>, <&rstgen 49>, <&rstgen 50>, <&rstgen 53>;
      reset-names   = "rst_axi", "rst_bpu", "rst_vce", "rst_apb", "rst_sram";
      starfive,vdec_noc_ctrl;
      power-domains = <&pwrc 3>;
      status        = "okay";
    };

    vpu_enc: vpu_enc@130b0000 {
      compatible    = "starfive,venc";
      dma-coherent;
      reg           = <0x00 0x130b0000 0x00 0x10000>;
      interrupts    = <0x0f>;
      clocks        = <&clkgen 78>, <&clkgen 79>, <&clkgen 80>, <&clkgen 81>, <&clkgen 82>;
      clock-names   = "axi_clk", "bpu_clk", "vce_clk", "apb_clk", "noc_bus";
      resets        = <&rstgen 54>, <&rstgen 55>, <&rstgen 56>, <&rstgen 57>, <&rstgen 58>;
      reset-names   = "rst_axi", "rst_bpu", "rst_vce", "rst_apb", "rst_sram";
      starfive,venc_noc_ctrl;
      power-domains = <&pwrc 6>;
      status        = "okay";
    };

    rstgen: reset-controller {
      compatible   = "starfive,jh7110-reset";
      reg          = <0x00 0x13020000 0x00 0x10000>, <0x00 0x10230000 0x00 0x10000>, <0x00 0x17000000 0x00 0x10000>, <0x00 0x19810000 0x00 0x10000>, <0x00 0x295c0000 0x00 0x10000>;
      reg-names    = "syscrg", "stgcrg", "aoncrg", "ispcrg", "voutcrg";
      #reset-cells = <0x01>;
      status       = "okay";
    };

    stmmac_axi_setup: stmmac-axi-config {
      snps,wr_osr_lmt = <0x0f>;
      snps,rd_osr_lmt = <0x0f>;
      snps,blen       = <0x100 0x80 0x40 0x20 0x00 0x00 0x00>;
    };

    gmac0: ethernet@16030000 {
      compatible                  = "starfive,dwmac", "snps,dwmac-5.10a";
      dma-coherent;
      reg                         = <0x00 0x16030000 0x00 0x10000>;
      clocks                      = <&clkgen 108>, <&clkgen 224>, <&clkgen 109>, <&clkgen 221>, <&clkgen 222>, <&clkgen 111>, <&clkgen 223>;
      clock-names                 = "gtx", "tx", "ptp_ref", "stmmaceth", "pclk", "gtxc", "rmii_rtx";
      resets                      = <&rstgen 161>, <&rstgen 160>;
      reset-names                 = "ahb", "stmmaceth";
      interrupts                  = <0x07 0x06 0x05>;
      interrupt-names             = "macirq", "eth_wake_irq", "eth_lpi";
      max-frame-size              = <9000>;
      phy-mode                    = "rgmii-id";
      snps,multicast-filter-bins  = <0x40>;
      snps,perfect-filter-entries = <0x80>;
      rx-fifo-depth               = <0x800>;
      tx-fifo-depth               = <0x800>;
      snps,fixed-burst;
      snps,no-pbl-x8;
      snps,force_thresh_dma_mode;
      snps,axi-config             = <&stmmac_axi_setup>;
      snps,tso;
      snps,en-tx-lpi-clockgating;
      snps,en-lpi;
      snps,write-requests         = <0x04>;
      snps,read-requests          = <0x04>;
      snps,burst-map              = <0x07>;
      snps,txpbl                  = <0x10>;
      snps,rxpbl                  = <0x10>;
      status                      = "okay";
      #address-cells              = <0x01>;
      #size-cells                 = <0x00>;

      phy0: ethernet-phy@0 {
        rgmii_sw_dr_2    = <0x00>;
        rgmii_sw_dr      = <0x03>;
        rgmii_sw_dr_rxc  = <0x06>;
        rxc_dly_en       = <0x00>;
        rx_delay_sel     = <0x0a>;
        tx_delay_sel_fe  = <0x05>;
        tx_delay_sel     = <0x0a>;
        tx_inverted_10   = <0x01>;
        tx_inverted_100  = <0x01>;
        tx_inverted_1000 = <0x01>;
      };
    };

    gmac1: ethernet@16040000 {
      compatible                  = "starfive,dwmac", "snps,dwmac-5.10a";
      dma-coherent;
      reg                         = <0x00 0x16040000 0x00 0x10000>;
      clocks                      = <&clkgen 100>, <&clkgen 105>, <&clkgen 102>, <&clkgen 97>, <&clkgen 98>, <&clkgen 107>, <&clkgen 101>;
      clock-names                 = "gtx", "tx", "ptp_ref", "stmmaceth", "pclk", "gtxc", "rmii_rtx";
      resets                      = <&rstgen 67>, <&rstgen 66>;
      reset-names                 = "ahb", "stmmaceth";
      interrupts                  = <0x4e 0x4d 0x4c>;
      interrupt-names             = "macirq", "eth_wake_irq", "eth_lpi";
      max-frame-size              = <9000>;
      phy-mode                    = "rgmii-id";
      snps,multicast-filter-bins  = <0x40>;
      snps,perfect-filter-entries = <0x80>;
      rx-fifo-depth               = <0x800>;
      tx-fifo-depth               = <0x800>;
      snps,fixed-burst;
      snps,no-pbl-x8;
      snps,force_thresh_dma_mode;
      snps,axi-config             = <&stmmac_axi_setup>;
      snps,tso;
      snps,en-tx-lpi-clockgating;
      snps,en-lpi;
      snps,write-requests         = <0x04>;
      snps,read-requests          = <0x04>;
      snps,burst-map              = <0x07>;
      snps,txpbl                  = <0x10>;
      snps,rxpbl                  = <0x10>;
      status                      = "okay";
      #address-cells              = <0x01>;
      #size-cells                 = <0x00>;

      phy1: ethernet-phy@1 {
        rgmii_sw_dr_2    = <0x00>;
        rgmii_sw_dr      = <0x03>;
        rgmii_sw_dr_rxc  = <0x06>;
        tx_delay_sel_fe  = <0x05>;
        tx_delay_sel     = <0x00>;
        rxc_dly_en       = <0x00>;
        rx_delay_sel     = <0x02>;
        tx_inverted_10   = <0x01>;
        tx_inverted_100  = <0x01>;
        tx_inverted_1000 = <0x00>;
      };
    };

    gpu: gpu@18000000 {
      compatible    = "img-gpu";
      reg           = <0x00 0x18000000 0x00 0x100000 0x00 0x130c000 0x00 0x10000>;
      clocks        = <&clkgen 45>, <&clkgen 48>, <&clkgen 49>, <&clkgen 46>, <&clkgen 47>, <&clkgen 50>;
      clock-names   = "clk_bv", "clk_apb", "clk_rtc", "clk_core", "clk_sys", "clk_axi";
      resets        = <&rstgen 21>, <&rstgen 22>;
      reset-names   = "rst_apb", "rst_doma";
      power-domains = <&pwrc 2>;
      interrupts    = <0x52>;
      current-clock = <8000000>;
      status        = "okay";
    };

    can0: can@130d0000 {
      compatible          = "starfive,jh7110-can", "ipms,can";
      reg                 = <0x00 0x130d0000 0x00 0x1000>;
      interrupts          = <0x70>;
      clocks              = <&clkgen 115>, <&clkgen 117>, <&clkgen 116>;
      clock-names         = "apb_clk", "core_clk", "timer_clk";
      resets              = <&rstgen 111>, <&rstgen 112>, <&rstgen 113>;
      reset-names         = "rst_apb", "rst_core", "rst_timer";
      frequency           = <40000000>;
      starfive,sys-syscon = <&sys_syscon 0x10 0x3 0x8>;
      syscon,can_or_canfd = <0x00>;
      status              = "disabled";
    };

    can1: can@130e0000 {
      compatible          = "starfive,jh7110-can", "ipms,can";
      reg                 = <0x00 0x130e0000 0x00 0x1000>;
      interrupts          = <0x71>;
      clocks              = <&clkgen 118>, <&clkgen 120>, <&clkgen 119>;
      clock-names         = "apb_clk", "core_clk", "timer_clk";
      resets              = <&rstgen 114>, <&rstgen 115>, <&rstgen 116>;
      reset-names         = "rst_apb", "rst_core", "rst_timer";
      frequency           = <40000000>;
      starfive,sys-syscon = <&sys_syscon 0x88 0x12 0x40000>;
      syscon,can_or_canfd = <0x00>;
      status              = "disabled";
    };

    tdm: tdm@10090000 {
      compatible       = "starfive,jh7110-tdm";
      reg              = <0x00 0x10090000 0x00 0x1000>;
      reg-names        = "tdm";
      clocks           = <&clkgen 184>, <&clkgen 185>, <&clkgen 186>, <&tdm_ext>, <&clkgen 187>, <&clkgen 17>;
      clock-names      = "clk_tdm_ahb", "clk_tdm_apb", "clk_tdm_internal", "clk_tdm_ext", "clk_tdm", "mclk_inner";
      resets           = <&rstgen 105>, <&rstgen 107>, <&rstgen 106>;
      reset-names      = "tdm_ahb", "tdm_apb", "tdm_rst";
      dmas             = <&dma 20>, <&dma 21>;
      dma-names        = "rx", "tx";
      #sound-dai-cells = <0x00>;
      status           = "disabled";
      pinctrl-names    = "default";
      pinctrl-0        = <&tdm0_pins>;
    };

    spdif0: spdif0@100a0000 {
      compatible       = "starfive,jh7110-spdif";
      reg              = <0x00 0x100a0000 0x00 0x1000>;
      clocks           = <&clkgen 159>, <&clkgen 160>, <&clkgen 16>, <&clkgen 17>, <&mclk_ext>, <&clkgen 18>;
      clock-names      = "spdif-apb", "spdif-core", "audroot", "mclk_inner", "mclk_ext", "mclk";
      resets           = <&rstgen 95>;
      reset-names      = "rst_apb";
      interrupts       = <0x54>;
      interrupt-names  = "tx";
      #sound-dai-cells = <0x00>;
      status           = "disabled";
    };

    pwmdac: pwmdac@100b0000 {
      compatible       = "starfive,jh7110-pwmdac";
      reg              = <0x00 0x100b0000 0x00 0x1000>;
      clocks           = <&clkgen 12>, <&clkgen 157>, <&clkgen 158>;
      clock-names      = "apb0", "pwmdac-apb", "pwmdac-core";
      resets           = <&rstgen 96>;
      reset-names      = "rst-apb";
      dmas             = <&dma 22>;
      dma-names        = "tx";
      #sound-dai-cells = <0x00>;
      status           = "okay";
      pinctrl-names    = "default";
      pinctrl-0        = <&pwmdac0_pins>;
    };

    i2stx: i2stx@100c0000 {
      compatible       = "snps,designware-i2stx";
      reg              = <0x00 0x100c0000 0x00 0x1000>;
      interrupt-names  = "tx";
      #sound-dai-cells = <0x00>;
      dmas             = <&dma 28>;
      dma-names        = "rx";
      status           = "disabled";
    };

    pdm: pdm@100d0000 {
      compatible       = "starfive,jh7110-pdm";
      reg              = <0x00 0x100d0000 0x00 0x1000>;
      reg-names        = "pdm";
      clocks           = <&clkgen 182>, <&clkgen 183>, <&clkgen 18>, <&mclk_ext>;
      clock-names      = "pdm_mclk", "pdm_apb", "clk_mclk", "mclk_ext";
      resets           = <&rstgen 97>, <&rstgen 98>;
      reset-names      = "pdm_dmic", "pdm_apb";
      #sound-dai-cells = <0x00>;
    };

    i2srx_mst: i2srx_mst@100e0000 {
      compatible          = "starfive,jh7110-i2srx-master";
      reg                 = <0x00 0x100e0000 0x00 0x1000>;
      clocks              = <&clkgen 12>, <&clkgen 175>, <&clkgen 176>, <&clkgen 178>, <&clkgen 179>, <&clkgen 181>, <&clkgen 18>, <&mclk_ext>;
      clock-names         = "apb0", "i2srx_apb", "i2srx_bclk_mst", "i2srx_lrck_mst", "i2srx_bclk", "i2srx_lrck", "mclk", "mclk_ext";
      resets              = <&rstgen 99>, <&rstgen 100>;
      reset-names         = "rst_apb_rx", "rst_bclk_rx";
      dmas                = <&dma 24>;
      dma-names           = "rx";
      starfive,sys-syscon = <&sys_syscon 0x18 0x34>;
      #sound-dai-cells    = <0x00>;
      status              = "disabled";
    };

    i2srx_3ch: i2srx_3ch@100e0000 {
      compatible          = "starfive,jh7110-i2srx", "snps,designware-i2s";
      reg                 = <0x00 0x100e0000 0x00 0x1000>;
      clocks              = <&clkgen 12>, <&clkgen 175>, <&clkgen 16>, <&clkgen 17>, <&clkgen 176>, <&clkgen 178>, <&clkgen 179>, <&clkgen 181>, <&clkgen 18>, <&mclk_ext>, <&i2srx_bclk_ext>, <&i2srx_lrck_ext>;
      clock-names         = "apb0", "3ch-apb", "audioroot", "mclk-inner", "bclk_mst", "3ch-lrck", "rx-bclk", "rx-lrck", "mclk", "mclk_ext", "bclk-ext", "lrck-ext";
      resets              = <&rstgen 99>, <&rstgen 100>;
      dmas                = <&dma 24>;
      dma-names           = "rx";
      starfive,sys-syscon = <&sys_syscon 0x18 0x34>;
      #sound-dai-cells    = <0x00>;
      status              = "disabled";
      pinctrl-names       = "default";
      pinctrl-0           = <&i2s_clk_pins &i2srx_pins>;
    };

    i2stx_4ch0: i2stx_4ch0@120b0000 {
      compatible       = "starfive,jh7110-i2stx-4ch0", "snps,designware-i2s";
      reg              = <0x00 0x120b0000 0x00 0x1000>;
      clocks           = <&clkgen 17>, <&clkgen 162>, <&clkgen 164>, <&clkgen 18>, <&clkgen 165>, <&clkgen 167>, <&clkgen 161>, <&mclk_ext>;
      clock-names      = "inner", "bclk-mst", "lrck-mst", "mclk", "bclk0", "lrck0", "i2s_apb", "mclk_ext";
      resets           = <&rstgen 101>, <&rstgen 102>;
      reset-names      = "rst_apb", "rst_bclk";
      dmas             = <&dma 47>;
      dma-names        = "tx";
      #sound-dai-cells = <0x00>;
      status           = "okay";
      pinctrl-names    = "default";
      pinctrl-0        = <&mclk_ext_pins>;
    };

    i2stx_4ch1: i2stx_4ch1@120c0000 {
      compatible       = "starfive,jh7110-i2stx-4ch1", "snps,designware-i2s";
      reg              = <0x00 0x120c0000 0x00 0x1000>;
      clocks           = <&clkgen 16>, <&clkgen 17>, <&clkgen 169>, <&clkgen 171>, <&clkgen 18>, <&clkgen 172>, <&clkgen 174>, <&clkgen 19>, <&clkgen 12>, <&clkgen 168>, <&mclk_ext>, <&i2stx_bclk_ext>, <&i2stx_lrck_ext>;
      clock-names      = "audroot", "mclk_inner", "bclk_mst", "lrck_mst", "mclk", "4chbclk", "4chlrck", "mclk_out", "apb0", "clk_apb", "mclk_ext", "bclk_ext", "lrck_ext";
      resets           = <&rstgen 103>, <&rstgen 104>;
      dmas             = <&dma 48>;
      dma-names        = "tx";
      #sound-dai-cells = <0x00>;
      status           = "disabled";
      pinctrl-names    = "default";
      pinctrl-0        = <&i2stx_pins>;
    };

    ptc: pwm@120d0000 {
      compatible           = "starfive,jh7110-pwm";
      reg                  = <0x00 0x120d0000 0x00 0x10000>;
      reg-names            = "control";
      clocks               = <&clkgen 121>;
      resets               = <&rstgen 108>;
      starfive,approx-freq = <0x1e8480>;
      #pwm-cells           = <0x03>;
      starfive,npwm        = <0x08>;
      status               = "okay";
      pinctrl-names        = "default";
      pinctrl-0            = <&pwm_pins>;
    };

    spdif_transmitter: spdif_transmitter {
      compatible       = "linux,spdif-dit";
      #sound-dai-cells = <0x00>;
      status           = "disabled";
    };

    pwmdac_codec: pwmdac-transmitter {
      compatible       = "starfive,jh7110-pwmdac-dit";
      #sound-dai-cells = <0x00>;
      status           = "okay";
    };

    dmic_codec: dmic_codec {
      compatible       = "dmic-codec";
      #sound-dai-cells = <0x00>;
      status           = "disabled";
    };

    spi0: spi@10060000 {
      compatible             = "arm,pl022", "arm,primecell";
      reg                    = <0x00 0x10060000 0x00 0x10000>;
      clocks                 = <&clkgen 131>;
      clock-names            = "apb_pclk";
      resets                 = <&rstgen 69>;
      reset-names            = "rst_apb";
      interrupts             = <0x26>;
      arm,primecell-periphid = <0x41022>;
      num-cs                 = <0x01>;
      #address-cells         = <0x01>;
      #size-cells            = <0x00>;
      status                 = "okay";
      pinctrl-names          = "default";
      pinctrl-0              = <&ssp0_pins>;

      spi_dev0: spi@0 {
        compatible        = "rohm,dh2228fv";
        pl022,com-mode    = <0x01>;
        spi-max-frequency = <10000000>;
        reg               = <0x00>;
        status            = "okay";
      };
    };

    spi1: spi@10070000 {
      compatible             = "arm,pl022", "arm,primecell";
      reg                    = <0x00 0x10070000 0x00 0x10000>;
      clocks                 = <&clkgen 132>;
      clock-names            = "apb_pclk";
      resets                 = <&rstgen 70>;
      reset-names            = "rst_apb";
      interrupts             = <0x27>;
      arm,primecell-periphid = <0x41022>;
      num-cs                 = <0x01>;
      #address-cells         = <0x01>;
      #size-cells            = <0x00>;
      status                 = "disabled";
    };

    spi2: spi@10080000 {
      compatible             = "arm,pl022", "arm,primecell";
      reg                    = <0x00 0x10080000 0x00 0x10000>;
      clocks                 = <&clkgen 133>;
      clock-names            = "apb_pclk";
      resets                 = <&rstgen 71>;
      reset-names            = "rst_apb";
      interrupts             = <0x28>;
      arm,primecell-periphid = <0x41022>;
      num-cs                 = <0x01>;
      #address-cells         = <0x01>;
      #size-cells            = <0x00>;
      status                 = "disabled";
    };

    spi3: spi@12070000 {
      compatible             = "arm,pl022", "arm,primecell";
      reg                    = <0x00 0x12070000 0x00 0x10000>;
      clocks                 = <&clkgen 134>;
      clock-names            = "apb_pclk";
      resets                 = <&rstgen 72>;
      reset-names            = "rst_apb";
      interrupts             = <0x34>;
      arm,primecell-periphid = <0x41022>;
      num-cs                 = <0x01>;
      #address-cells         = <0x01>;
      #size-cells            = <0x00>;
      status                 = "disabled";
    };

    spi4: spi@12080000 {
      compatible             = "arm,pl022", "arm,primecell";
      reg                    = <0x00 0x12080000 0x00 0x10000>;
      clocks                 = <&clkgen 135>;
      clock-names            = "apb_pclk";
      resets                 = <&rstgen 73>;
      reset-names            = "rst_apb";
      interrupts             = <0x35>;
      arm,primecell-periphid = <0x41022>;
      num-cs                 = <0x01>;
      #address-cells         = <0x01>;
      #size-cells            = <0x00>;
      status                 = "disabled";
    };

    spi5: spi@12090000 {
      compatible             = "arm,pl022", "arm,primecell";
      reg                    = <0x00 0x12090000 0x00 0x10000>;
      clocks                 = <&clkgen 136>;
      clock-names            = "apb_pclk";
      resets                 = <&rstgen 74>;
      reset-names            = "rst_apb";
      interrupts             = <0x36>;
      arm,primecell-periphid = <0x41022>;
      num-cs                 = <0x01>;
      #address-cells         = <0x01>;
      #size-cells            = <0x00>;
      status                 = "disabled";
    };

    spi6: spi@120a0000 {
      compatible             = "arm,pl022", "arm,primecell";
      reg                    = <0x00 0x120a0000 0x00 0x10000>;
      clocks                 = <&clkgen 137>;
      clock-names            = "apb_pclk";
      resets                 = <&rstgen 75>;
      reset-names            = "rst_apb";
      interrupts             = <0x37>;
      arm,primecell-periphid = <0x41022>;
      num-cs                 = <0x01>;
      #address-cells         = <0x01>;
      #size-cells            = <0x00>;
      status                 = "disabled";
    };

    pcie0: pcie@2b000000 {
      compatible          = "starfive,jh7110-pcie", "plda,pci-xpressrich3-axi";
      dma-coherent;
      #address-cells      = <0x03>;
      #size-cells         = <0x02>;
      #interrupt-cells    = <0x01>;
      reg                 = <0x00 0x2b000000 0x00 0x1000000 0x09 0x40000000 0x00 0x10000000>;
      reg-names           = "reg", "config";
      device_type         = "pci";
      starfive,stg-syscon = <&stg_syscon 0xc0 0xc4 0x130 0x1b8>;
      starfive,phyctrl    = <&phyctrl0 0x28 0x80>;
      bus-range           = <0x00 0xff>;
      ranges              = <0x82000000 0x00 0x30000000 0x00 0x30000000 0x00 0x8000000 0xc3000000 0x09 0x00 0x09 0x00 0x00 0x40000000>;
      msi-parent          = <&plic>;
      interrupts          = <0x38>;
      interrupt-controller;
      interrupt-names     = "msi";
      interrupt-parent    = <&plic>;
      interrupt-map-mask  = <0x00 0x00 0x00 0x07>;
      interrupt-map       = <0x0 0x0 0x0 0x1 &plic 0x1>, <0x0 0x0 0x0 0x2 &plic 0x2>, <0x0 0x0 0x0 0x3 &plic 0x3>, <0x0 0x0 0x0 0x4 &plic 0x4>;
      clocks              = <&clkgen 96>, <&clkgen 200>, <&clkgen 198>, <&clkgen 199>;
      clock-names         = "noc", "tl", "axi_mst0", "apb";
      resets              = <&rstgen 139>, <&rstgen 140>, <&rstgen 141>, <&rstgen 142>, <&rstgen 143>, <&rstgen 144>;
      reset-names         = "rst_mst0", "rst_slv0", "rst_slv", "rst_brg", "rst_core", "rst_apb";
      status              = "okay";
      pinctrl-names       = "default";
      pinctrl-0           = <&pcie0_wake_default>, <&pcie0_clkreq_default>;
      reset-gpios         = <&gpio 26 1>;
    };

    pcie1: pcie@2c000000 {
      compatible          = "starfive,jh7110-pcie", "plda,pci-xpressrich3-axi";
      dma-coherent;
      #address-cells      = <0x03>;
      #size-cells         = <0x02>;
      #interrupt-cells    = <0x01>;
      reg                 = <0x00 0x2c000000 0x00 0x1000000 0x09 0xc0000000 0x00 0x10000000>;
      reg-names           = "reg", "config";
      device_type         = "pci";
      starfive,stg-syscon = <&stg_syscon 0x270 0x274 0x2e0 0x368>;
      starfive,phyctrl    = <&phyctrl1 0x28 0x80>;
      bus-range           = <0x00 0xff>;
      ranges              = <0x82000000 0x00 0x38000000 0x00 0x38000000 0x00 0x8000000 0xc3000000 0x09 0x80000000 0x09 0x80000000 0x00 0x40000000>;
      msi-parent          = <&plic>;
      interrupts          = <0x39>;
      interrupt-controller;
      interrupt-names     = "msi";
      interrupt-parent    = <&plic>;
      interrupt-map-mask  = <0x00 0x00 0x00 0x07>;
      interrupt-map       = <0x0 0x0 0x0 0x1 &plic 0x1>, <0x0 0x0 0x0 0x2 &plic 0x2>, <0x0 0x0 0x0 0x3 &plic 0x3>, <0x0 0x0 0x0 0x4 &plic 0x4>;
      clocks              = <&clkgen 96>, <&clkgen 203>, <&clkgen 201>, <&clkgen 202>;
      clock-names         = "noc", "tl", "axi_mst0", "apb";
      resets              = <&rstgen 145>, <&rstgen 146>, <&rstgen 147>, <&rstgen 148>, <&rstgen 149>, <&rstgen 150>;
      reset-names         = "rst_mst0", "rst_slv0", "rst_slv", "rst_brg", "rst_core", "rst_apb";
      status              = "okay";
      pinctrl-names       = "default";
      pinctrl-0           = <&pcie1_wake_default>, <&pcie1_clkreq_default>;
      reset-gpios         = <&gpio 28 1>;
    };

    mailbox_contrl0: mailbox@13060000 {
      compatible  = "starfive,mail_box";
      reg         = <0x00 0x13060000 0x00 0x1000>;
      clocks      = <&clkgen 113>;
      clock-names = "clk_apb";
      resets      = <&rstgen 68>;
      reset-names = "mbx_rre";
      interrupts  = <0x1a 0x1b>;
      #mbox-cells = <0x02>;
      status      = "okay";
    };

    display: display-subsystem {
      compatible = "starfive,jh7110-display", "verisilicon,display-subsystem";
      ports      = <&dc_out_dpi0>;
      status     = "okay";
    };

    dssctrl: dssctrl@295b0000 {
      compatible = "starfive,jh7110-dssctrl", "verisilicon,dss-ctrl", "syscon";
      reg        = <0x00 0x295b0000 0x00 0x90>;
    };

    tda988x_pin: tda988x_pin {
      compatible = "starfive,tda998x_rgb_pin";
      status     = "disabled";
    };

    rgb_output: rgb-output {
      compatible = "starfive,jh7110-rgb_output", "verisilicon,rgb-encoder";
      status     = "disabled";

      ports {
        #address-cells = <0x01>;
        #size-cells    = <0x00>;

        port@0 {
          #address-cells = <0x01>;
          #size-cells    = <0x00>;
          reg            = <0x00>;

          hdmi_input0: endpoint@0 {
            reg             = <0x00>;
            remote-endpoint = <&dc_out_dpi0>;
          };
        };
      };
    };

    dc8200: dc8200@29400000 {
      compatible             = "starfive,jh7110-dc8200", "verisilicon,dc8200";
      verisilicon,dss-syscon = <&dssctrl>;
      reg                    = <0x00 0x29400000 0x00 0x100>, <0x00 0x29400800 0x00 0x2000>, <0x00 0x17030000 0x00 0x1000>;
      interrupts             = <0x5f>;
      status                 = "okay";
      clocks                 = <&clkgen 60>, <&clkgen 58>, <&clkgen 62>, <&clkgen 61>, <&clkvout 7>, <&clkvout 8>, <&clkvout 4>, <&clkvout 5>, <&clkvout 6>, <&clkgen 62>, <&clkvout 9>, <&hdmitx0_pixelclk>, <&clkvout 1>, <&clkvout 39>, <&clkvout 40>;
      clock-names            = "noc_disp", "vout_src", "top_vout_axi", "top_vout_ahb", "pix_clk", "vout_pix1", "axi_clk", "core_clk", "vout_ahb", "vout_top_axi", "vout_top_lcd", "hdmitx0_pixelclk", "dc8200_pix0", "dc8200_pix0_out", "dc8200_pix1_out";
      resets                 = <&rstgen 43>, <&rstgen 224>, <&rstgen 225>, <&rstgen 226>, <&rstgen 26>;
      reset-names            = "rst_vout_src", "rst_axi", "rst_ahb", "rst_core", "rst_noc_disp";

      dc_out: port {
        #address-cells = <0x01>;
        #size-cells    = <0x00>;

        dc_out_dpi0: endpoint@0 {
          reg             = <0x00>;
          remote-endpoint = <&hdmi_input0>;
        };

        dc_out_dpi1: endpoint@1 {
          reg             = <0x01>;
          remote-endpoint = <&hdmi_in_lcdc>;
        };

        dc_out_dpi2: endpoint@2 {
          reg             = <0x02>;
          remote-endpoint = <&mipi_in>;
        };
      };
    };

    dsi_output: dsi-output {
      compatible = "starfive,jh7110-display-encoder", "verisilicon,dsi-encoder";
      status     = "okay";

      ports {
        #address-cells = <0x01>;
        #size-cells    = <0x00>;

        port@0 {
          reg = <0x00>;

          mipi_in: endpoint {
            remote-endpoint = <&dc_out_dpi2>;
          };
        };

        port@1 {
          reg = <0x01>;

          sf_dpi_output: endpoint {
            remote-endpoint = <&dsi_in_port>;
          };
        };
      };
    };

    mipi_dphy: mipi-dphy@295e0000 {
      compatible  = "starfive,jh7110-mipi-dphy-tx", "m31,mipi-dphy-tx";
      reg         = <0x00 0x295e0000 0x00 0x10000>;
      clocks      = <&clkvout 14>;
      clock-names = "dphy_txesc";
      resets      = <&rstgen 234>, <&rstgen 235>;
      reset-names = "dphy_sys", "dphy_txbytehs";
      #phy-cells  = <0x00>;
      status      = "okay";
    };

    mipi_dsi: mipi@295d0000 {
      compatible  = "starfive,jh7110-mipi_dsi", "cdns,dsi";
      reg         = <0x00 0x295d0000 0x00 0x10000>;
      interrupts  = <0x62>;
      reg-names   = "dsi";
      clocks      = <&clkvout 11>, <&clkvout 10>, <&clkvout 13>, <&clkvout 12>;
      clock-names = "sys", "apb", "txesc", "dpi";
      resets      = <&rstgen 227>, <&rstgen 228>, <&rstgen 229>, <&rstgen 230>, <&rstgen 231>, <&rstgen 232>;
      reset-names = "dsi_dpi", "dsi_apb", "dsi_rxesc", "dsi_sys", "dsi_txbytehs", "dsi_txesc";
      phys        = <&mipi_dphy>;
      phy-names   = "dphy";
      status      = "okay";

      ports {
        #address-cells = <0x01>;
        #size-cells    = <0x00>;

        port@0 {
          reg            = <0x00>;
          #address-cells = <0x01>;
          #size-cells    = <0x00>;

          dsi0_output: endpoint@0 {
            reg             = <0x00>;
            remote-endpoint = <&panel_out0>;
          };

          dsi1_output: endpoint@1 {
            reg             = <0x01>;
            remote-endpoint = <&panel_out1>;
          };
        };

        port@1 {
          reg = <0x01>;

          dsi_in_port: endpoint {
            remote-endpoint = <&sf_dpi_output>;
          };
        };
      };
    };

    hdmi: hdmi@29590000 {
      compatible       = "starfive,jh7110-hdmi", "inno,hdmi";
      reg              = <0x00 0x29590000 0x00 0x4000>;
      interrupts       = <0x63>;
      status           = "okay";
      clocks           = <&clkvout 17>, <&clkvout 15>, <&clkvout 16>, <&hdmitx0_pixelclk>;
      clock-names      = "sysclk", "mclk", "bclk", "pclk";
      resets           = <&rstgen 233>;
      reset-names      = "hdmi_tx";
      #sound-dai-cells = <0x00>;
      pinctrl-names    = "default";
      pinctrl-0        = <&inno_hdmi_pins>;
      hpd-gpio         = <&gpio 15 0>;

      hdmi_in: port {
        #address-cells = <0x01>;
        #size-cells    = <0x00>;

        hdmi_in_lcdc: endpoint@0 {
          reg             = <0x00>;
          remote-endpoint = <&dc_out_dpi1>;
        };
      };
    };

    sound0: snd-card0 {
      compatible             = "simple-audio-card";
      simple-audio-card,name = "Starfive-AC108-Sound-Card";
      #address-cells         = <0x01>;
      #size-cells            = <0x00>;
    };

    sound1: snd-card1 {
      compatible             = "simple-audio-card";
      simple-audio-card,name = "Starfive-HDMI-Sound-Card";
      #address-cells         = <0x01>;
      #size-cells            = <0x00>;

      simple-audio-card,dai-link@0 {
        reg             = <0x00>;
        format          = "i2s";
        bitclock-master = <&sndi2s0>;
        frame-master    = <&sndi2s0>;
        mclk-fs         = <0x100>;
        status          = "okay";

        sndi2s0: cpu {
          sound-dai = <&i2stx_4ch0>;
        };

        sndhdmi0: codec {
          sound-dai = <&hdmi>;
        };
      };
    };

    sound2: snd-card2 {
      compatible             = "simple-audio-card";
      simple-audio-card,name = "Starfive-PDM-Sound-Card";
      #address-cells         = <0x01>;
      #size-cells            = <0x00>;
    };

    sound3: snd-card3 {
      compatible             = "simple-audio-card";
      simple-audio-card,name = "Starfive-PWMDAC-Sound-Card";
      #address-cells         = <0x01>;
      #size-cells            = <0x00>;

      simple-audio-card,dai-link@0 {
        reg             = <0x00>;
        format          = "left_j";
        bitclock-master = <&sndcpu0>;
        frame-master    = <&sndcpu0>;
        status          = "okay";

        sndcpu0: cpu {
          sound-dai = <&pwmdac>;
        };

        codec {
          sound-dai = <&pwmdac_codec>;
        };
      };
    };

    sound4: snd-card4 {
      compatible             = "simple-audio-card";
      simple-audio-card,name = "Starfive-SPDIF-Sound-Card";
      #address-cells         = <0x01>;
      #size-cells            = <0x00>;
    };

    sound5: snd-card5 {
      compatible             = "simple-audio-card";
      simple-audio-card,name = "Starfive-TDM-Sound-Card";
      #address-cells         = <0x01>;
      #size-cells            = <0x00>;
    };

    sound6: snd-card6 {
      compatible             = "simple-audio-card";
      simple-audio-card,name = "Starfive-WM8960-Sound-Card";
      #address-cells         = <0x01>;
      #size-cells            = <0x00>;
    };

    co_process: e24@6e210000 {
      compatible          = "starfive,e24";
      dma-coherent;
      reg                 = <0x00 0x6e210000 0x00 0x1000 0x00 0x6e211000 0x00 0x3f000>;
      reg-names           = "ecmd", "espace";
      clocks              = <&clkgen 214>, <&clkgen 215>, <&clkgen 216>;
      clock-names         = "clk_rtc", "clk_core", "clk_dbg";
      resets              = <&rstgen 132>;
      reset-names         = "e24_core";
      starfive,stg-syscon = <&stg_syscon>;
      interrupt-parent    = <&plic>;
      firmware-name       = "e24_elf";
      irq-mode            = <0x01>;
      mbox-names          = "tx", "rx";
      mboxes              = <&mailbox_contrl0 0 2>, <&mailbox_contrl0 2 0>;
      #address-cells      = <0x01>;
      #size-cells         = <0x01>;
      ranges              = <0x6ce00000 0x00 0x6ce00000 0x1600000>;
      status              = "okay";
      memory-region       = <&e24_mem>;

      dsp@0 { };
    };

    sof_dsp: sof_dsp@20020000 {
      compatible          = "starfive,vf2-dsp-v1";
      dma-coherent;
      reg                 = <0x00 0x20020000 0x00 0x10000>;
      clocks              = <&clkgen 190>;
      clock-names         = "core_clk";
      resets              = <&rstgen 129>, <&rstgen 130>;
      reset-names         = "rst_core", "rst_axi";
      starfive,stg-syscon = <&stg_syscon>;
      mbox-names          = "tx", "rx";
      mboxes              = <&mailbox_contrl0 0 1>, <&mailbox_contrl0 1 0>;
      #address-cells      = <0x01>;
      #size-cells         = <0x01>;
      status              = "disabled";
      memory-region       = <&hifi4_reserved>;
    };

    starfive_cpufreq: starfive,jh7110-cpufreq {
      compatible  = "starfive,jh7110-cpufreq";
      clocks      = <&clkgen 1>;
      clock-names = "cpu_clk";
    };
  };

  aliases {
    spi0      = &qspi;
    gpio0     = &gpio;
    ethernet0 = &gmac0;
    ethernet1 = &gmac1;
    mmc0      = &sdio0;
    mmc1      = &sdio1;
    serial0   = &uart0;
    serial3   = &uart3;
    i2c0      = &i2c0;
    i2c1      = &i2c1;
    i2c2      = &i2c2;
    i2c3      = &i2c3;
    i2c4      = &i2c4;
    i2c5      = &i2c5;
    i2c6      = &i2c6;
  };

  chosen {
    stdout-path = "/soc/serial@10000000";
  };

  memory@40000000 {
    device_type = "memory";
    reg         = <0x00 0x40000000 0x01 0x00>;
  };

  reserved-memory {
    #address-cells = <2>;
    #size-cells = <2>;
    ranges;

    e24_mem: e24@c0000000 {
      reg = <0x0 0x6ce00000 0x0 0x1600000>;
    };

    hifi4_reserved: hifi4@f0000000 {
      reg = <0x0 0x69c00000 0x0 0x03001000>;
    };
  };

  leds {
    compatible = "gpio-leds";

    led-ack {
      gpios                 = <&gpioa 3 0>;
      color                 = <0x02>;
      function              = "heartbeat";
      linux,default-trigger = "heartbeat";
      label                 = "ack";
    };
  };

  backlight: backlight {
    compatible               = "pwm-backlight";
    pwms                     = <&ptc 2 5000000 1>;
    status                   = "okay";
    brightness-levels        = <0x00 0x01 0x02 0x03 0x04 0x05 0x06 0x07 0x08 0x09 0x0a 0x0b 0x0c 0x0d 0x0e 0x0f 0x10 0x11 0x12 0x13 0x14 0x15 0x16 0x17 0x18 0x19 0x1a 0x1b 0x1c 0x1d 0x1e 0x1f 0x20 0x21 0x22 0x23 0x24 0x25 0x26 0x27 0x28 0x29 0x2a 0x2b 0x2c 0x2d 0x2e 0x2f 0x30 0x31 0x32 0x33 0x34 0x35 0x36 0x37 0x38 0x39 0x3a 0x3b 0x3c 0x3d 0x3e 0x3f 0x40 0x41 0x42 0x43 0x44 0x45 0x46 0x47 0x48 0x49 0x4a 0x4b 0x4c 0x4d 0x4e 0x4f 0x50 0x51 0x52 0x53 0x54 0x55 0x56 0x57 0x58 0x59 0x5a 0x5b 0x5c 0x5d 0x5e 0x5f 0x60 0x61 0x62 0x63 0x64 0x65 0x66 0x67 0x68 0x69 0x6a 0x6b 0x6c 0x6d 0x6e 0x6f 0x70 0x71 0x72 0x73 0x74 0x75 0x76 0x77 0x78 0x79 0x7a 0x7b 0x7c 0x7d 0x7e 0x7f 0x80 0x81 0x82 0x83 0x84 0x85 0x86 0x87 0x88 0x89 0x8a 0x8b 0x8c 0x8d 0x8e 0x8f 0x90 0x91 0x92 0x93 0x94 0x95 0x96 0x97 0x98 0x99 0x9a 0x9b 0x9c 0x9d 0x9e 0x9f 0xa0 0xa1 0xa2 0xa3 0xa4 0xa5 0xa6 0xa7 0xa8 0xa9 0xaa 0xab 0xac 0xad 0xae 0xaf 0xb0 0xb1 0xb2 0xb3 0xb4 0xb5 0xb6 0xb7 0xb8 0xb9 0xba 0xbb 0xbc 0xbd 0xbe 0xbf 0xc0 0xc1 0xc2 0xc3 0xc4 0xc5 0xc6 0xc7 0xc8 0xc9 0xca 0xcb 0xcc 0xcd 0xce 0xcf 0xd0 0xd1 0xd2 0xd3 0xd4 0xd5 0xd6 0xd7 0xd8 0xd9 0xda 0xdb 0xdc 0xdd 0xde 0xdf 0xe0 0xe1 0xe2 0xe3 0xe4 0xe5 0xe6 0xe7 0xe8 0xe9 0xea 0xeb 0xec 0xed 0xee 0xef 0xf0 0xf1 0xf2 0xf3 0xf4 0xf5 0xf6 0xf7 0xf8 0xf9 0xfa 0xfb 0xfc 0xfd 0xfe 0xff>;
    default-brightness-level = <0xff>;
  };

  gpio-restart {
    compatible = "gpio-restart";
    gpios      = <&gpio 35 0>;
    priority   = <0xa0>;
  };
};
